AUTOSAR XML (schema 00047)
standard types defined: boolean, uint16, uint32, uint8
package /Application/AdaptiveApplicationSwComponentTypes
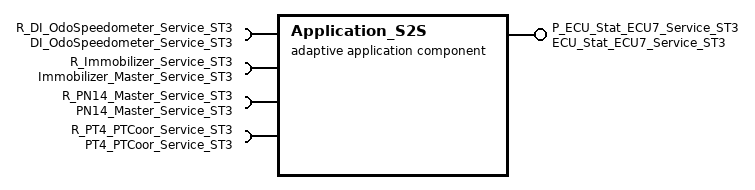
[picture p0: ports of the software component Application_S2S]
  adaptive application sw component type Application_S2S
    provide port P_ECU_Stat_ECU7_Service_ST3: provided-interface=ECU_Stat_ECU7_Service_ST3
    4 x require port:
      R_DI_OdoSpeedometer_Service_ST3: required-interface=DI_OdoSpeedometer_Service_ST3
      R_Immobilizer_Service_ST3: required-interface=Immobilizer_Master_Service_ST3
      R_PN14_Master_Service_ST3: required-interface=PN14_Master_Service_ST3
      R_PT4_PTCoor_Service_ST3: required-interface=PT4_PTCoor_Service_ST3
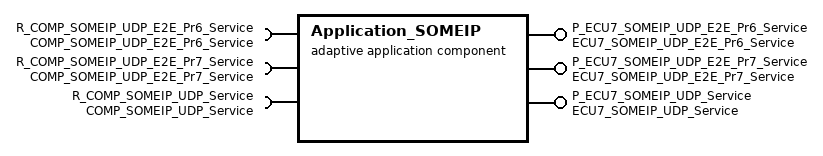
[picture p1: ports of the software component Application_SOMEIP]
  adaptive application sw component type Application_SOMEIP
    provide port P_ECU7_SOMEIP_UDP_E2E_Pr6_Service: provided-interface=ECU7_SOMEIP_UDP_E2E_Pr6_Service
    provide port P_ECU7_SOMEIP_UDP_E2E_Pr7_Service: provided-interface=ECU7_SOMEIP_UDP_E2E_Pr7_Service
    provide port P_ECU7_SOMEIP_UDP_Service: provided-interface=ECU7_SOMEIP_UDP_Service
    require port R_COMP_SOMEIP_UDP_E2E_Pr6_Service: required-interface=COMP_SOMEIP_UDP_E2E_Pr6_Service
    require port R_COMP_SOMEIP_UDP_E2E_Pr7_Service: required-interface=COMP_SOMEIP_UDP_E2E_Pr7_Service
    require port R_COMP_SOMEIP_UDP_Service: required-interface=COMP_SOMEIP_UDP_Service
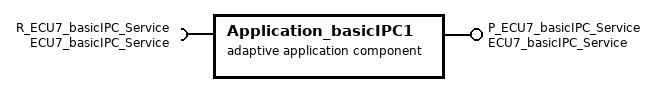
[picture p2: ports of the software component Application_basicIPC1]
  adaptive application sw component type Application_basicIPC1
    provide port P_ECU7_basicIPC_Service: provided-interface=ECU7_basicIPC_Service
    require port R_ECU7_basicIPC_Service: required-interface=ECU7_basicIPC_Service
  adaptive application sw component type Application_basicIPC2
    require port R_ECU7_basicIPC_Service: required-interface=ECU7_basicIPC_Service
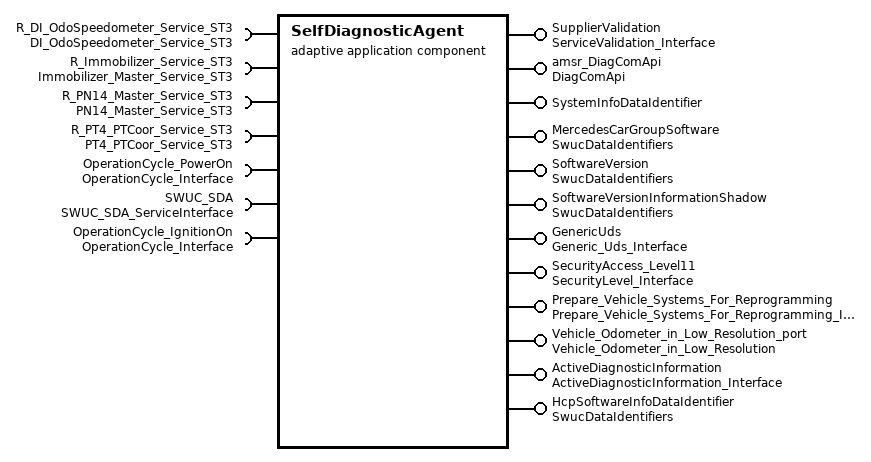
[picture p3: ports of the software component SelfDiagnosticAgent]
  adaptive application sw component type SelfDiagnosticAgent
    12 x provide port:
      SupplierValidation: provided-interface=ServiceValidation_Interface
      amsr_DiagComApi: provided-interface=DiagComApi
      SystemInfoDataIdentifier: provided-interface=SystemInfoDataIdentifier
      MercedesCarGroupSoftware: provided-interface=SwucDataIdentifiers
      SoftwareVersion: provided-interface=SwucDataIdentifiers
      SoftwareVersionInformationShadow: provided-interface=SwucDataIdentifiers
      GenericUds: provided-interface=Generic_Uds_Interface
      SecurityAccess_Level11: provided-interface=SecurityLevel_Interface
      Prepare_Vehicle_Systems_For_Reprogramming: provided-interface=Prepare_Vehicle_Systems_For_Reprogramming_Interface
      Vehicle_Odometer_in_Low_Resolution_port: provided-interface=Vehicle_Odometer_in_Low_Resolution
      ActiveDiagnosticInformation: provided-interface=ActiveDiagnosticInformation_Interface
      HcpSoftwareInfoDataIdentifier: provided-interface=SwucDataIdentifiers
    provide/require port prPortPrototype_FileStorage: provided-required-interface=PersistencyInterface_FileSotrage_PRPort
    provide/require port prPortPrototype_KeyValueStorage: provided-required-interface=PersistencyInterface_PRPort
    7 x require port:
      R_DI_OdoSpeedometer_Service_ST3: required-interface=DI_OdoSpeedometer_Service_ST3
      R_Immobilizer_Service_ST3: required-interface=Immobilizer_Master_Service_ST3
      R_PN14_Master_Service_ST3: required-interface=PN14_Master_Service_ST3
      R_PT4_PTCoor_Service_ST3: required-interface=PT4_PTCoor_Service_ST3
      OperationCycle_PowerOn: required-interface=OperationCycle_Interface
      SWUC_SDA: required-interface=SWUC_SDA_ServiceInterface
      OperationCycle_IgnitionOn: required-interface=OperationCycle_Interface
    adaptive swc internal behavior AdaptiveInternalBehavior
      13 x swc service dependency:
        OperationCyclePowerOn: assigned-ports=role-based-port-assignment={port-prototype=OperationCycle_PowerOn, role=SomeOtherRole}
        SwcDependency_SystemInfoDataIdentifier_Port: assigned-ports=role-based-port-assignment={port-prototype=SystemInfoDataIdentifier, role=DataServices}
        SwcDependency_MercedesCarGroupSoftware_Port: assigned-ports=role-based-port-assignment={port-prototype=MercedesCarGroupSoftware, role=DataServices}
        SwcDependency_SoftwareVersion_Port: assigned-ports=role-based-port-assignment={port-prototype=SoftwareVersion, role=DataServices}
        SwcDependency_SoftwareVersionInformationShadow_Port: assigned-ports=role-based-port-assignment={port-prototype=SoftwareVersionInformationShadow, role=DataServices}
        OperationCycleIgnitionOn: assigned-ports=role-based-port-assignment={port-prototype=OperationCycle_IgnitionOn, role=SomeOtherRole}
        SwcDependency_ServiceValidation_Supplier: assigned-ports=role-based-port-assignment={port-prototype=SupplierValidation, role=ServiceValidation}
          service-needs:
            diagnostic communication manager needs Supplier: service-request-callback-type=REQUEST-CALLBACK-TYPE-SUPPLIER
        GenericUds: assigned-ports=role-based-port-assignment={port-prototype=GenericUds, role=SomeOtherRole}
        SecurityAccess_Level11: assigned-ports=role-based-port-assignment={port-prototype=SecurityAccess_Level11, role=SomeOtherRole}
        Prepare_Vehicle_Systems_For_Reprogramming: assigned-ports=role-based-port-assignment={port-prototype=Prepare_Vehicle_Systems_For_Reprogramming, role=RoutineServices}
        SwcDependency_Vehicle_Odometer_in_Low_Resolution_Port: assigned-ports=role-based-port-assignment={port-prototype=Vehicle_Odometer_in_Low_Resolution_port, role=DataServices}
        SwcDependency_ActiveDiagnosticInformation_Port: assigned-ports=role-based-port-assignment={port-prototype=ActiveDiagnosticInformation, role=RoutineServices}
        SwcDependency_HcpSoftwareInfoDataIdentifier_Port: assigned-ports=role-based-port-assignment={port-prototype=HcpSoftwareInfoDataIdentifier, role=DataServices}
package /Application/Executables
  6 x executable, all with version=1.00.00.0000:
    Application_S2S_Executable: category=APPLICATION_LEVEL, build-type=BUILD-TYPE-DEBUG
      root sw component prototype Application_S2S_ExecutableRootSwc: application-type=Application_S2S
    Application_SOMEIP_Executable: category=APPLICATION_LEVEL, build-type=BUILD-TYPE-DEBUG
      root sw component prototype Application_SOMEIP_ExecutableRootSwc: application-type=Application_SOMEIP
    Application_basicIPC1_Executable: category=APPLICATION_LEVEL, build-type=BUILD-TYPE-DEBUG
      root sw component prototype Application_basicIPC1_ExecutableRootSwc: application-type=Application_basicIPC1
    Application_basicIPC2_Executable: category=APPLICATION_LEVEL, build-type=BUILD-TYPE-DEBUG
      root sw component prototype Application_basicIPC2_ExecutableRootSwc: application-type=Application_basicIPC2
    SelfDiagnosticAgent_Executable: category=APPLICATION_LEVEL, build-type=BUILD-TYPE-DEBUG
      root sw component prototype SelfDiagnosticAgent_ExecutableRootSwc: application-type=SelfDiagnosticAgent
    DiagnosticManagerDeamonExecutable: category=PLATFORM_LEVEL
      root sw component prototype DiagnosticManagerDeamonExecutableRootSwc: application-type=DiagnosticManagerSwc
package /ApplicationDeployment/Processes
  6 x process:
    Application_S2S_Process: executable=Application_S2S_Executable, state-dependent-startup-config{function-group-state=MachineState.Running, startup-config=STARTUP_CONFIG_DEFAULT}
    Application_SOMEIP_Process: executable=Application_SOMEIP_Executable, state-dependent-startup-config{function-group-state=MachineState.Running, startup-config=STARTUP_CONFIG_DEFAULT}
      process state machine ProcessStateMachine_Application_SOMEIP: type=MachineStates
    Application_basicIPC1_Process: executable=Application_basicIPC1_Executable, state-dependent-startup-config{function-group-state=MachineState.Running, startup-config=STARTUP_CONFIG_DEFAULT}
      process state machine ProcessStateMachine_Application_basicIPC1: type=MachineStates
    Application_basicIPC2_Process: executable=Application_basicIPC2_Executable, state-dependent-startup-config{function-group-state=MachineState.Running, startup-config=STARTUP_CONFIG_DEFAULT}
      process state machine ProcessStateMachine_Application_basicIPC2: type=MachineStates
    SelfDiagnosticAgent_Process: executable=SelfDiagnosticAgent_Executable, state-dependent-startup-config{function-group-state=MachineState.Running, startup-config=STARTUP_CONFIG_DEFAULT}
    DiagnosticManagerDeamon: design=DiagnosticManagerDeamonDesign, executable=DiagnosticManagerDeamonExecutable, state-dependent-startup-config{function-group-state=[MachineState.Startup, MachineState.Running], startup-config=STARTUP_CONFIG_DEFAULT}
package /ApplicationDeployment/ProcessDesigns
  6 x process design:
    Application_basicIPC1_ProcessDesign: executable=Application_basicIPC1_Executable
    Application_basicIPC2_ProcessDesign: executable=Application_basicIPC2_Executable
    DiagnosticManagerDeamonDesign: executable=DiagnosticManagerDeamonExecutable
    Application_SOMEIP_ProcessDesign: executable=Application_SOMEIP_Executable
    Application_S2S_ProcessDesign: executable=Application_S2S_Executable
    SelfDiagnosticAgent_ProcessDesign: executable=SelfDiagnosticAgent_Executable
package /Communication/PDUs
  general purpose pdu SD_Ctrl_Rx: category=SD, length=1472
  general purpose pdu SD_Ctrl_Rx_Multicast: category=SD, length=1472
  general purpose pdu SD_Ctrl_Tx: category=SD, length=1472
  pdu DI_OdoSpeedometer_ST3: length=8, unused-bit-pattern=255  # DriverInformation Odometer and speedometer
    signal CRC_DI_Odo_Pr5_ST3: start 0, 16 bit, little-endian, data-type-policy=OVERRIDE, i-signal-type=PRIMITIVE, base-type=uint16, range raw 0..65535 "16_CRC_w/oSNA_ImportedAdaptivePilot", to ECU7_ExecutionContext1  # CRC-checksum of signal group according to AUTOSAR Profile 5
    signal SQC_DI_Odo_Pr5_ST3: start 16, 8 bit, little-endian, data-type-policy=OVERRIDE, i-signal-type=PRIMITIVE, base-type=uint8, compu {identical}, range raw 0..255 "08_0-255_1_SNA=-", to ECU7_ExecutionContext1  # Sequence counter
    signal Odo_ST3: start 24, 24 bit, little-endian, data-type-policy=OVERRIDE, i-signal-type=PRIMITIVE, base-type=uint32, invalid-value=16777215, compu {phys=raw*0.1 for raw 0..9999999, 16777214=I_C24_KM_0_999999K9_0K1_INVLD_SNA_INVLD (INVLD) (Invalid), 16777215=I_C24_KM_0_999999K9_0K1_INVLD_SNA_SNA (SNA) (SNA value from data type); unit km}, range phys 0..1677721.5 "24_km_0-999999,9_0,1_Invld_SNA", to ECU7_ExecutionContext1  # Odometer (for everyone)
    mapping DI_Odo_Pr5_ST3: i-signal-group=DI_Odo_Pr5_ST3, transfer-property=PENDING
    mapping VehSpd_Disp_ST3: transfer-property=PENDING
  pdu ECU_Stat_ECU7_ST3: length=8, unused-bit-pattern=0  # ECU state
    signal ECU_Id_ECU7_ST3: start 0, 12 bit, little-endian, data-type-policy=OVERRIDE, i-signal-type=PRIMITIVE, base-type=uint16, invalid-value=4095, compu {phys=raw for raw 0..4094, 4095=I_C12_0_4094_1_SNA_SNA (SNA) (SNA value from data type)}, range phys 0..4095 "12_0-4094_1_SNA", transfer-property=PENDING  # ECU identifier
    signal WakeupRsn_ECU7_ST3: start 20, 10 bit, little-endian, data-type-policy=OVERRIDE, i-signal-type=PRIMITIVE, base-type=uint16, invalid-value=1023, compu {0=I_C10_WAKEUPRSN_ST3_NETWORK (NETWORK) (Wakeup by network), 1=I_C10_WAKEUPRSN_ST3_NW_MAIN (NW_MAIN) (Wakeup by MAIN Ethernet), 11=I_C10_WAKEUPRSN_ST3_NW_HEADUNIT1 (NW_HEADUNIT1) (Wakeup by HEADUNIT1 CAN), 12=I_C10_WAKEUPRSN_ST3_NW_HEADUNIT2 (NW_HEADUNIT2) (Wakeup by HEADUNIT2 CAN), 13=I_C10_WAKEUPRSN_ST3_NW_PERIPHERY (NW_PERIPHERY) (Wakeup by PERIPHERY CAN), 14=I_C10_WAKEUPRSN_ST3_NW_BODY1 (NW_BODY1) (Wakeup by BODY1 CAN), 15=I_C10_WAKEUPRSN_ST3_NW_CHASSIS (NW_CHASSIS) (Wakeup by CHASSIS FlexRay), 16=I_C10_WAKEUPRSN_ST3_NW_RADAR_R (NW_RADAR_R) (Wakeup by RADAR_R CAN), 17=I_C10_WAKEUPRSN_ST3_NW_RADAR_F (NW_RADAR_F) (Wakeup by RADAR_F CAN), 18=I_C10_WAKEUPRSN_ST3_NW_OBD_PTI (NW_OBD_PTI) (Wakeup by OBD_PTI CAN), 19=I_C10_WAKEUPRSN_ST3_NW_STEERING_WHEEL (NW_STEERING_WHEEL) (Wakeup by STEERING_WHEEL CAN), 20=I_C10_WAKEUPRSN_ST3_NW_CPC (NW_CPC) (Wakeup by CPC CAN), 21=I_C10_WAKEUPRSN_ST3_NW_ECM (NW_ECM) (Wakeup by ECM CAN), 22=I_C10_WAKEUPRSN_ST3_NW_ENERGY (NW_ENERGY) (Wakeup by ENERGY CAN), 23=I_C10_WAKEUPRSN_ST3_NW_INV (NW_INV) (Wakeup by INV CAN), 24=I_C10_WAKEUPRSN_ST3_NW_TCM (NW_TCM) (Wakeup by TCM CAN), 25=I_C10_WAKEUPRSN_ST3_NW_AEPU (NW_AEPU) (Wakeup by AEPU CAN), 26=I_C10_WAKEUPRSN_ST3_NW_BODY2 (NW_BODY2) (Wakeup by BODY2 CAN), 27=I_C10_WAKEUPRSN_ST3_NW_BODY3 (NW_BODY3) (Wakeup by BODY3 CAN), 28=I_C10_WAKEUPRSN_ST3_NW_CAL_COC (NW_CAL_COC) (Wakeup by CAL_COC CAN), 29=I_C10_WAKEUPRSN_ST3_NW_CAL_DL (NW_CAL_DL) (Wakeup by CAL_DL CAN), 30=I_C10_WAKEUPRSN_ST3_NW_CAL_DR (NW_CAL_DR) (Wakeup by CAL_DR CAN), 31=I_C10_WAKEUPRSN_ST3_NW_ECM_PERIPHERY1 (NW_ECM_PERIPHERY1) (Wakeup by ECM_PERIPHERY1 CAN), 32=I_C10_WAKEUPRSN_ST3_NW_ECM_PERIPHERY2 (NW_ECM_PERIPHERY2) (Wakeup by ECM_PERIPHERY2 CAN), 33=I_C10_WAKEUPRSN_ST3_NW_ENGINE_PT3 (NW_ENGINE_PT3) (Wakeup by ENGINE_PT3 CAN), 34=I_C10_WAKEUPRSN_ST3_NW_HAD_BACKUP (NW_HAD_BACKUP) (Wakeup by HAD_BACKUP CAN), 35=I_C10_WAKEUPRSN_ST3_NW_HYBRID_PT3 (NW_HYBRID_PT3) (Wakeup by HYBRID_PT3 CAN), 36=I_C10_WAKEUPRSN_ST3_NW_LSM_F (NW_LSM_F) (Wakeup by LSM_F CAN), 37=I_C10_WAKEUPRSN_ST3_NW_POWERTRAIN_PT3 (NW_POWERTRAIN_PT3) (Wakeup by POWERTRAIN_PT3 CAN), 38=I_C10_WAKEUPRSN_ST3_NW_PT_SENSOR_PT3 (NW_PT_SENSOR_PT3) (Wakeup by PT_SENSOR_PT3 CAN), 39=I_C10_WAKEUPRSN_ST3_NW_RVC_HSVL (NW_RVC_HSVL) (Wakeup by RVC_HSVL CAN), 40=I_C10_WAKEUPRSN_ST3_NW_SPV (NW_SPV) (Wakeup by SPV CAN), 41=I_C10_WAKEUPRSN_ST3_NW_SUSPENSION_F (NW_SUSPENSION_F) (Wakeup by SUSPENSION_F CAN), 42=I_C10_WAKEUPRSN_ST3_NW_SUSPENSION_R (NW_SUSPENSION_R) (Wakeup by SUSPENSION_R CAN), 43=I_C10_WAKEUPRSN_ST3_NW_EIS_BASE_GW (NW_EIS_BASE_GW) (Wakeup by EIS_BASE_GW CAN), 44=I_C10_WAKEUPRSN_ST3_NW_EIS_GW_BASE (NW_EIS_GW_BASE) (Wakeup by EIS_GW_BASE CAN), 45=I_C10_WAKEUPRSN_ST3_NW_AUXILIARY1 (NW_AUXILIARY1) (Wakeup by AUXILIARY1 CAN), 46=I_C10_WAKEUPRSN_ST3_NW_AUXILIARY2 (NW_AUXILIARY2) (Wakeup by AUXILIARY2 CAN), 47=I_C10_WAKEUPRSN_ST3_NW_DRIVE_UNIT (NW_DRIVE_UNIT) (Wakeup by DRIVE_UNIT CAN), 48=I_C10_WAKEUPRSN_ST3_NW_INLET (NW_INLET) (Wakeup by INLET CAN), 49=I_C10_WAKEUPRSN_ST3_NW_BODY4 (NW_BODY4) (Wakeup by BODY4 CAN), 115=I_C10_WAKEUPRSN_ST3_LIN_HVAC_F (LIN_HVAC_F) (Wakeup by LIN-Slave HVAC_F), 116=I_C10_WAKEUPRSN_ST3_LIN_HVAC_R (LIN_HVAC_R) (Wakeup by LIN-Slave HVAC_R), 117=I_C10_WAKEUPRSN_ST3_LIN_VCS (LIN_VCS) (Wakeup by LIN-Slave VCS), 118=I_C10_WAKEUPRSN_ST3_LIN_WPRA (LIN_WPRA) (Wakeup by LIN-Slave WPRA), 119=I_C10_WAKEUPRSN_ST3_LIN_IHTM_RC (LIN_IHTM_RC) (Wakeup by LIN-Slave IHTM_RC), 120=I_C10_WAKEUPRSN_ST3_LIN_PTC48_R (LIN_PTC48_R) (Wakeup by LIN-Slave PTC48_R), 121=I_C10_WAKEUPRSN_ST3_LIN_AQS (LIN_AQS) (Wakeup by LIN-Slave AQS), 122=I_C10_WAKEUPRSN_ST3_LIN_ECP2_1 (LIN_ECP2_1) (Wakeup by LIN-Slave ECP2_1), 123=I_C10_WAKEUPRSN_ST3_LIN_EXV1 (LIN_EXV1) (Wakeup by LIN-Slave EXV1), 124=I_C10_WAKEUPRSN_ST3_LIN_IHTM (LIN_IHTM) (Wakeup by LIN-Slave IHTM), 125=I_C10_WAKEUPRSN_ST3_LIN_EAC (LIN_EAC) (Wakeup by LIN-Slave EAC), 126=I_C10_WAKEUPRSN_ST3_LIN_EAC48 (LIN_EAC48) (Wakeup by LIN-Slave EAC48), 127=I_C10_WAKEUPRSN_ST3_LIN_PTC_HV (LIN_PTC_HV) (Wakeup by LIN-Slave PTC_HV), 128=I_C10_WAKEUPRSN_ST3_TERM_15 (TERM_15) (Wakeup by discrete terminal 15 signal), 130=I_C10_WAKEUPRSN_ST3_TERM_54 (TERM_54) (Wakeup by terminal 54 active), 131=I_C10_WAKEUPRSN_ST3_LIN_HFA (LIN_HFA) (Wakeup by LIN-Slave Hands Free Access), 132=I_C10_WAKEUPRSN_ST3_LIN_IBS (LIN_IBS) (Wakeup by LIN-Slave Battery sensor), 133=I_C10_WAKEUPRSN_ST3_LIN_DOOR_HANDLE (LIN_DOOR_HANDLE) (Wakeup by LIN-Slave Door Handle), 134=I_C10_WAKEUPRSN_ST3_LIN_LISB48 (LIN_LISB48) (Wakeup by LIN-Slave LISB48), 135=I_C10_WAKEUPRSN_ST3_CMN_ECU_RST_POR (CMN_ECU_RST_POR) (Wakeup by ECU Power On Reset, Common Reason), 136=I_C10_WAKEUPRSN_ST3_CMN_ECU_RST_DIAG (CMN_ECU_RST_DIAG) (Wakeup by ECU Diagnostic Reset, Common Reason), 137=I_C10_WAKEUPRSN_ST3_CMN_ECU_RST_TEST (CMN_ECU_RST_TEST) (Wakeup by ECU Test Reset, Common Reason), 138=I_C10_WAKEUPRSN_ST3_CMN_ECU_RST_ERR (CMN_ECU_RST_ERR) (Wakeup by ECU Error Reset, Common Reason), 139=I_C10_WAKEUPRSN_ST3_CMN_ETH_WAKEUPLINE (CMN_ETH_WAKEUPLINE) (Wakeup by Ethernet Wakeup-Line, Common Reason), 140=I_C10_WAKEUPRSN_ST3_CMN_AFTERRUN (CMN_AFTERRUN) (Wakeup by afterrun, Common Reason), 141=I_C10_WAKEUPRSN_ST3_CRASH (CRASH) (Wakeup by crash signal), 142=I_C10_WAKEUPRSN_ST3_LIN_VCI (LIN_VCI) (Wakeup by LIN-Slave VCI), 143=I_C10_WAKEUPRSN_ST3_LIN_CIS (LIN_CIS) (Wakeup by LIN-Slave CIS), 181=I_C10_WAKEUPRSN_ST3_EASY_ENTRY_ACTV (EASY_ENTRY_ACTV) (Wakeup by Easy Entry active), 183=I_C10_WAKEUPRSN_ST3_ERR_SEAT_HTVN (ERR_SEAT_HTVN) (Wakeup by error seat heating/ventilation), 184=I_C10_WAKEUPRSN_ST3_ERR_SEAT_CHM (ERR_SEAT_CHM) (Wakeup by error console heating), 199=I_C10_WAKEUPRSN_ST3_VEHSL_EVENT (VEHSL_EVENT) (Wakeup by Vehicle State Living signal update), 200=I_C10_WAKEUPRSN_ST3_RLS (RLS) (Wakeup by rotary light switch), 201=I_C10_WAKEUPRSN_ST3_EF_KEY (EF_KEY) (Wakeup by emergency flasher key), 202=I_C10_WAKEUPRSN_ST3_RHU_FT (RHU_FT) (Wakeup by residual heat utilization front), 203=I_C10_WAKEUPRSN_ST3_RHU_R (RHU_R) (Wakeup by residual heat utilization rear), 204=I_C10_WAKEUPRSN_ST3_ICH_RQ (ICH_RQ) (Wakeup by idependent car heater request), 205=I_C10_WAKEUPRSN_ST3_VPRZR_VN (VPRZR_VN) (Wakeup by Vaporizer ventilation), 206=I_C10_WAKEUPRSN_ST3_PRECON (PRECON) (Wakeup by PreConditioning), 207=I_C10_WAKEUPRSN_ST3_SOL_VN (SOL_VN) (Wakeup by Solar Ventilation), 208=I_C10_WAKEUPRSN_ST3_EXTLGT_ACTV (EXTLGT_ACTV) (Wakeup by exterior lighting active), 209=I_C10_WAKEUPRSN_ST3_INTLGT_ACTV (INTLGT_ACTV) (Wakeup by interior lighting active), 210=I_C10_WAKEUPRSN_ST3_TSSR_ACTV (TSSR_ACTV) (Wakeup by TSSR active), 211=I_C10_WAKEUPRSN_ST3_SEAT_HT_F_ACTV (SEAT_HT_F_ACTV) (Wakeup by seat heating front active), 212=I_C10_WAKEUPRSN_ST3_SEAT_HT_R_ACTV (SEAT_HT_R_ACTV) (Wakeup by seat heating rear active), 213=I_C10_WAKEUPRSN_ST3_SEAT_VN_F_ACTV (SEAT_VN_F_ACTV) (Wakeup by seat ventilation front active), 214=I_C10_WAKEUPRSN_ST3_SEAT_VN_R_ACTV (SEAT_VN_R_ACTV) (Wakeup by seat ventilation rear active), 215=I_C10_WAKEUPRSN_ST3_EHS_3S (EHS_3S) (Wakeup by 3S engine hood switch (Pawl)), 216=I_C10_WAKEUPRSN_ST3_T58D_POTI (T58D_POTI) (Wakeup by terminal 58d potentiometer), 217=I_C10_WAKEUPRSN_ST3_DRB (DRB) (Wakeup by Double Roller Blind), 218=I_C10_WAKEUPRSN_ST3_BKRST_UNLK_RM (BKRST_UNLK_RM) (Wakeup by Backrest Unlock rear Middle), 219=I_C10_WAKEUPRSN_ST3_DL_SW2_PSD (DL_SW2_PSD) (Wakeup by Deck Lid Switch Pressed 2), 220=I_C10_WAKEUPRSN_ST3_DL_SW (DL_SW) (Wakeup by deck lid switch pressed), 221=I_C10_WAKEUPRSN_ST3_BGC_SW (BGC_SW) (Wakeup by switch inside baggage compartment pressed), 222=I_C10_WAKEUPRSN_ST3_BKRST_RL_LK_UNLK (BKRST_RL_LK_UNLK) (Wakeup by back rest rear left locked or unlocked), 223=I_C10_WAKEUPRSN_ST3_BKRST_RR_LK_UNLK (BKRST_RR_LK_UNLK) (Wakeup by back rest rear right locked or unlocked), 224=I_C10_WAKEUPRSN_ST3_DL_CLS_LK_SW (DL_CLS_LK_SW) (Wakeup by deck lid switch close/lock close pressed), 225=I_C10_WAKEUPRSN_ST3_DL_RLTCH (DL_RLTCH) (Wakeup by deck lid rotary latch pressed), 226=I_C10_WAKEUPRSN_ST3_BKRST_3L_LK_UNLK (BKRST_3L_LK_UNLK) (Wakeup by back rest 3rd row left locked or unlocked), 227=I_C10_WAKEUPRSN_ST3_BKRST_3R_LK_UNLK (BKRST_3R_LK_UNLK) (Wakeup by back rest 3rd row right locked or unlocked), 228=I_C10_WAKEUPRSN_ST3_GAS_DR_SW (GAS_DR_SW) (Wakeup by gas door switch), 229=I_C10_WAKEUPRSN_ST3_AILCF (AILCF) (Wakeup by AILCF), 230=I_C10_WAKEUPRSN_ST3_AILCC (AILCC) (Wakeup by AILCC), 256=I_C10_WAKEUPRSN_ST3_TRLR_ELEC_ACT (TRLR_ELEC_ACT) (Wakeup by electrical trailer hitch activation), 257=I_C10_WAKEUPRSN_ST3_TRLR_DET (TRLR_DET) (Wakeup by trailer detected), 258=I_C10_WAKEUPRSN_ST3_DL_LK (DL_LK) (Wakeup by delayed locking), 259=I_C10_WAKEUPRSN_ST3_START_SW_PSD (START_SW_PSD) (Wakeup by start switch pressed), 260=I_C10_WAKEUPRSN_ST3_RADIO_DATA (RADIO_DATA) (Wakeup by radio data), 261=I_C10_WAKEUPRSN_ST3_RLTCH_DR (RLTCH_DR) (Wakeup by rotational latch door), 263=I_C10_WAKEUPRSN_ST3_PKBRKSW (PKBRKSW) (Wakeup by Parking switch pressed), 264=I_C10_WAKEUPRSN_ST3_KEYLESS_GO (KEYLESS_GO) (Wakeup by Keyless Go/Start (Core 1/0)), 265=I_C10_WAKEUPRSN_ST3_PNM12 (PNM12) (Wakeup by Power network management 12V), 266=I_C10_WAKEUPRSN_ST3_PNM48 (PNM48) (Wakeup by Power network management 48V), 267=I_C10_WAKEUPRSN_ST3_BAT48_LOWCHARGE (BAT48_LOWCHARGE) (Wakeup by 48V battery due to low charge), 270=I_C10_WAKEUPRSN_ST3_PN14_IODM (PN14_IODM) (Wakeup by IOD Measurement), 271=I_C10_WAKEUPRSN_ST3_PN14_REMSRV_STAT (PN14_REMSRV_STAT) (Wakeup by Change of Remote Service Status), 272=I_C10_WAKEUPRSN_ST3_PN14_DDP (PN14_DDP) (Wakeup by Deep Discharge Protection), 273=I_C10_WAKEUPRSN_ST3_PN14_LOWCHARGE (PN14_LOWCHARGE) (Wakeup by low charge of the battery), 274=I_C10_WAKEUPRSN_ST3_PN14_REMODHV12V (PN14_REMODHV12V) (Wakeup by reload mode HV 12V), 275=I_C10_WAKEUPRSN_ST3_PN14_DLM (PN14_DLM) (Wakeup by Powernet CutOff (Dynamic Load Management)), 276=I_C10_WAKEUPRSN_ST3_SDC_PN2_LOWCHARGE (SDC_PN2_LOWCHARGE) (Wakeup by low charge of the battery in SDC_PNM2), 277=I_C10_WAKEUPRSN_ST3_SDC_PN2_REMODHV12V (SDC_PN2_REMODHV12V) (Wakeup by reload mode HV 12 in SDC_PNM2), 280=I_C10_WAKEUPRSN_ST3_DATA_EXCHG (DATA_EXCHG) (Wakeup by data exchange with vehicle functions), 281=I_C10_WAKEUPRSN_ST3_INTERNET_CON (INTERNET_CON) (Wakeup by internet connection), 282=I_C10_WAKEUPRSN_ST3_CMN_USER_DATA (CMN_USER_DATA) (Wakeup by user data, Common Reason), 290=I_C10_WAKEUPRSN_ST3_CMN_SERV_LOCAL (CMN_SERV_LOCAL) (Wakeup by local activated service, Common Reason), 291=I_C10_WAKEUPRSN_ST3_CMN_SERV_REM (CMN_SERV_REM) (Wakeup by remote activated service, Common Reason), 292=I_C10_WAKEUPRSN_ST3_VEH_REAR_LOWERING (VEH_REAR_LOWERING) (Wakeup by vehicle rear lowering), 300=I_C10_WAKEUPRSN_ST3_CMN_BTN_PSD (CMN_BTN_PSD) (Wakeup by button pressed, Common Reason), 301=I_C10_WAKEUPRSN_ST3_FLAP_PSD (FLAP_PSD) (Wakeup by flap pressed), 302=I_C10_WAKEUPRSN_ST3_CHADEMO (CHADEMO) (Wakeup by CHADEMO charging system), 303=I_C10_WAKEUPRSN_ST3_GBT (GBT) (Wakeup by GBT charging system), 304=I_C10_WAKEUPRSN_ST3_CMN_PROXIMITY (CMN_PROXIMITY) (Wakeup by proximity, Common Reason), 305=I_C10_WAKEUPRSN_ST3_CTRL_PILOT (CTRL_PILOT) (Wakeup by control pilot), 306=I_C10_WAKEUPRSN_ST3_CMN_HV_DET (CMN_HV_DET) (Wakeup by HiVolt detection, Common Reason), 307=I_C10_WAKEUPRSN_ST3_CMN_CHRG_TMR (CMN_CHRG_TMR) (Wakeup by charging timer, Common Reason), 308=I_C10_WAKEUPRSN_ST3_TRCT_BAT_OP_STRATEGY (TRCT_BAT_OP_STRATEGY) (Wakeup by traction battery operating strategy), 309=I_C10_WAKEUPRSN_ST3_VTA (VTA) (Wakeup by VTA alarm), 310=I_C10_WAKEUPRSN_ST3_PDD (PDD) (Wakeup by PDD collision detected), 311=I_C10_WAKEUPRSN_ST3_UNEQUAL_STRING_VOLT (UNEQUAL_STRING_VOLT) (Wakeup by unequal string voltages), 312=I_C10_WAKEUPRSN_ST3_MUTE_ACTV (MUTE_ACTV) (Wakeup by mute activated), 313=I_C10_WAKEUPRSN_ST3_VIDEO_RQ (VIDEO_RQ) (Wakeup by video in request), 314=I_C10_WAKEUPRSN_ST3_ALARM_ACTV (ALARM_ACTV) (Wakeup by alarm activation), 315=I_C10_WAKEUPRSN_ST3_RECIRC_AIR_RQ (RECIRC_AIR_RQ) (Wakeup by FLA/NFS recirc air request), 316=I_C10_WAKEUPRSN_ST3_TPM_SYNC (TPM_SYNC) (Wakeup by TPM synchronize BackEndServer), 320=I_C10_WAKEUPRSN_ST3_DI_DISP_RQ (DI_DISP_RQ) (Wakeup by DI display request), 321=I_C10_WAKEUPRSN_ST3_DI_IND_RQ (DI_IND_RQ) (Wakeup by DI indicator request), 322=I_C10_WAKEUPRSN_ST3_HUD_RQ (HUD_RQ) (Wakeup by HUD request), 325=I_C10_WAKEUPRSN_ST3_MSG_DISP_RQ (MSG_DISP_RQ) (Wakeup by message display request), 326=I_C10_WAKEUPRSN_ST3_ROOF_LMP_ON_RQ (ROOF_LMP_ON_RQ) (Wakeup by rooflamps on request), 327=I_C10_WAKEUPRSN_ST3_IL_ON_RQ (IL_ON_RQ) (Wakeup by interior light activated from special vehicle), 328=I_C10_WAKEUPRSN_ST3_SPS_APPL (SPS_APPL) (Wakeup by special vehicle application), 330=I_C10_WAKEUPRSN_ST3_PWC_WRAPPER (PWC_WRAPPER) (Wakeup by PWC Wrapper), 331=I_C10_WAKEUPRSN_ST3_PW_SW (PW_SW) (Wakeup by power window switch), 332=I_C10_WAKEUPRSN_ST3_CLKS_SW (CLKS_SW) (Wakeup by centrol locking system switch), 333=I_C10_WAKEUPRSN_ST3_SEAT_SW (SEAT_SW) (Wakeup by seat switch), 334=I_C10_WAKEUPRSN_ST3_DL_REM_SW (DL_REM_SW) (Wakeup by deck lid remote switch), 335=I_C10_WAKEUPRSN_ST3_TANK_UNLK_SW (TANK_UNLK_SW) (Wakeup by tank unlock switch), 336=I_C10_WAKEUPRSN_ST3_SLTCH_DR (SLTCH_DR) (Wakeup by secondary latch), 337=I_C10_WAKEUPRSN_ST3_INSRLVR_SW (INSRLVR_SW) (Wakeup by inside release lever switch), 338=I_C10_WAKEUPRSN_ST3_OUTSRLVR_SW (OUTSRLVR_SW) (Wakeup by outside release lever switch), 339=I_C10_WAKEUPRSN_ST3_TRL_HTCH_SW (TRL_HTCH_SW) (Wakeup by trailer hitch switch), 340=I_C10_WAKEUPRSN_ST3_TSSR_R_RB_SW (TSSR_R_RB_SW) (Wakeup by TSSR switch), 341=I_C10_WAKEUPRSN_ST3_CSL_SW (CSL_SW) (Wakeup by child security switch), 342=I_C10_WAKEUPRSN_ST3_GEAR_SW (GEAR_SW) (Wakeup by gear switch), 343=I_C10_WAKEUPRSN_ST3_AD_SW (AD_SW) (Wakeup by automated door switch), 344=I_C10_WAKEUPRSN_ST3_T2R_SW (T2R_SW) (Wakeup by automated door Tip2Run), 345=I_C10_WAKEUPRSN_ST3_HV_INTERLOCK_ERR (HV_INTERLOCK_ERR) (Wakeup by interlock error), 346=I_C10_WAKEUPRSN_ST3_NFC (NFC) (Wakeup by NFC), 347=I_C10_WAKEUPRSN_ST3_POLLING (POLLING) (Wakeup by Polling (COD belonging to the car was detected)), 348=I_C10_WAKEUPRSN_ST3_TSL_P_PSD (TSL_P_PSD) (Wakeup by Transmission Selector Lever P button pressed), 349=I_C10_WAKEUPRSN_ST3_STWHL_LVR_PSD (STWHL_LVR_PSD) (Wakeup by Steering Wheel Lever pressed), 350=I_C10_WAKEUPRSN_ST3_BAT14_DDP (BAT14_DDP) (Wakeup by Deep discharge protection), 351=I_C10_WAKEUPRSN_ST3_BAT14_LOWCHARGE (BAT14_LOWCHARGE) (Wakeup by low charge of the 12V battery), 352=I_C10_WAKEUPRSN_ST3_BAT14_CHARGECURR (BAT14_CHARGECURR) (Wakeup by charge Current detection), 353=I_C10_WAKEUPRSN_ST3_BAT14_IODM (BAT14_IODM) (Wakeup by IOD Measurement), 354=I_C10_WAKEUPRSN_ST3_BAT14_IODAVG (BAT14_IODAVG) (Wakeup by Average IOD Measurement), 400=I_C10_WAKEUPRSN_ST3_FOTA_TMR (FOTA_TMR) (Wakeup by FOTA Timer), 1020=I_C10_WAKEUPRSN_ST3_RESERVE_3 (RESERVE_3) (Wakeup by Reserve 3), 1021=I_C10_WAKEUPRSN_ST3_RESERVE_2 (RESERVE_2) (Wakeup by Reserve 2), 1022=I_C10_WAKEUPRSN_ST3_RESERVE_1 (RESERVE_1) (Wakeup by Reserve 1), 1023=I_C10_WAKEUPRSN_ST3_SNA (SNA) (SNA value from data type)} "1 - 99: Networks,e.g. MAIN Wakeup by MAIN - CHASSIS Wakeup by CHASSIS -ENGINE Wakeup by ENGINE | What about LIN? 100 - 1022: ECU-specific wakeup reasons, generically so that the reasons can be used by all ECUs", range raw 0..1023 "10_WakeupRsn_ST3", transfer-property=PENDING  # Wakeup reason
    signal Awake_Diag_Actv_ECU7_ST3: start 30, 1 bit, little-endian, data-type-policy=OVERRIDE, i-signal-type=PRIMITIVE, base-type=boolean, transfer-property=PENDING  # Stay awake for diagnostics active
    signal Awake_NwStart_ECU7_ST3: start 31, 1 bit, little-endian, data-type-policy=OVERRIDE, i-signal-type=PRIMITIVE, base-type=boolean, transfer-property=PENDING  # Stay awake for network startup
    signal Awake_HAD_Actv_ECU7_ST3: start 32, 1 bit, little-endian, data-type-policy=OVERRIDE, i-signal-type=PRIMITIVE, base-type=boolean, transfer-property=PENDING  # Stay awake for HAD active
    signal Awake_Ignition_On_ECU7_ST3: start 33, 1 bit, little-endian, data-type-policy=OVERRIDE, i-signal-type=PRIMITIVE, base-type=boolean, transfer-property=PENDING  # Stay awake for ignition on from ECU7
  pdu Ign_Stat_ST3: length=4, minimum-delay=0.02, unused-bit-pattern=255  # Ignition state
    signal CRC_Ign_Stat_Pr5_ST3: start 0, 16 bit, little-endian, data-type-policy=OVERRIDE, i-signal-type=PRIMITIVE, base-type=uint16, range raw 0..65535 "16_CRC_w/oSNA_ImportedAdaptivePilot", transfer-property=PENDING, to ECU7_ExecutionContext1  # CRC-checksum of signal group according to AUTOSAR Profile 5
    signal SQC_Ign_Stat_Pr5_ST3: start 16, 8 bit, little-endian, data-type-policy=OVERRIDE, i-signal-type=PRIMITIVE, base-type=uint8, compu {identical}, range phys 0..255 "08_0-255_1_SNA=-", transfer-property=PENDING, to ECU7_ExecutionContext1  # Sequence counter
    signal ISw_Stat_ST3: start 24, 3 bit, little-endian, data-type-policy=OVERRIDE, i-signal-type=PRIMITIVE, base-type=uint8, invalid-value=7, compu {0=I_C03_ISW_STAT_IGN_LOCK (IGN_LOCK) (Ignition lock (0)), 1=I_C03_ISW_STAT_IGN_OFF (IGN_OFF) (Ignition off (15c)), 2=I_C03_ISW_STAT_IGN_ACC (IGN_ACC) (Ignition accessory (15r)), 4=I_C03_ISW_STAT_IGN_ON (IGN_ON) (Ignition on (15)), 5=I_C03_ISW_STAT_IGN_START (IGN_START) (Ignition start (50)), 7=I_C03_ISW_STAT_SNA (SNA) (SNA value from data type)}, range raw 0..7 "03_ISw_Stat", to ECU7_ExecutionContext1  # Ignition switch state
    signal Veh_Op_Mode_ST3: start 27, 4 bit, little-endian, data-type-policy=OVERRIDE, i-signal-type=PRIMITIVE, base-type=uint8, invalid-value=15, compu {0=I_C04_VEHOPMODE_DRV (DRV) (Drive), 1=I_C04_VEHOPMODE_DIAG (DIAG) (Diagnostic), 2=I_C04_VEHOPMODE_REMSTART_PRECON (REMSTART_PRECON) (Remote_start preconditioning), 3=I_C04_VEHOPMODE_ENG_RUN_CONT (ENG_RUN_CONT) (Engine continuos running), 4=I_C04_VEHOPMODE_KEY_PARK (KEY_PARK) (Key_parking), 5=I_C04_VEHOPMODE_REMSTART_BAT_CHRG (REMSTART_BAT_CHRG) (Remote start battery charge), 6=I_C04_VEHOPMODE_AVP (AVP) (Automated Valet Parking), 7=I_C04_VEHOPMODE_SDC (SDC) (Self Driving Car), 15=I_C04_VEHOPMODE_SNA (SNA) (SNA value from data type)}, range raw 0..15 "04_VehOpMode", transfer-property=PENDING, to ECU7_ExecutionContext1  # Operating Mode Vehicle
    signal KG_StartSw_Psd_ST3: start 31, 1 bit, little-endian, data-type-policy=OVERRIDE, i-signal-type=PRIMITIVE, base-type=boolean, transfer-property=PENDING, to ECU7_ExecutionContext1  # Keyless Go start switch pressed
    mapping Ign_Stat_Pr5_ST3: i-signal-group=Ign_Stat_Pr5_ST3, transfer-property=TRIGGERED-ON-CHANGE
  pdu PN14_Master_Stat1_ST3: length=8, unused-bit-pattern=255  # Powernetwork 12V master state
    signal PN14_TransMd_Stat_ST3: start 0, 2 bit, little-endian, data-type-policy=OVERRIDE, i-signal-type=PRIMITIVE, base-type=uint8, invalid-value=3, compu {0=I_C02_TRANSMD_STAT_OFF (OFF) (Transport mode permanently off), 1=I_C02_TRANSMD_STAT_TEMP_OFF (TEMP_OFF) (Transport mode temporarily off), 2=I_C02_TRANSMD_STAT_ACTV (ACTV) (Transport mode active), 3=I_C02_TRANSMD_STAT_SNA (SNA) (SNA value from data type)}, range raw 0..3 "02_TransMd_Stat", transfer-property=PENDING, to ECU7_ExecutionContext1  # Powernet transport mode status
    signal PN14_ProdMd_Stat_ST3: start 5, 3 bit, little-endian, data-type-policy=OVERRIDE, i-signal-type=PRIMITIVE, base-type=uint8, invalid-value=7, compu {0=I_C03_PN14_PRODMD_STAT_ST3_OFF (OFF) (Productionmode off), 1=I_C03_PN14_PRODMD_STAT_ST3_ON (ON) (Productionmode active), 2=I_C03_PN14_PRODMD_STAT_ST3_SF01 (SF01) (Productionmode Special Funcion 1), 3=I_C03_PN14_PRODMD_STAT_ST3_SF02 (SF02) (Productionmode Special Funcion 2), 4=I_C03_PN14_PRODMD_STAT_ST3_SF03 (SF03) (Productionmode Special Funcion 3), 7=I_C03_PN14_PRODMD_STAT_ST3_SNA (SNA) (SNA value from data type)}, range raw 0..7 "03_PN14_ProdMd_Stat_ST3", transfer-property=PENDING, to ECU7_ExecutionContext1  # Powernet production mode state
    signal PN14_SupBat_Volt_ST3: start 22, 10 bit, little-endian, data-type-policy=OVERRIDE, i-signal-type=PRIMITIVE, base-type=uint16, invalid-value=1023, compu {phys=raw*0.025 for raw 0..1022, 1023=I_C10_V_0_25K55_0K025_SNA (SNA) (SNA value from data type); unit V}, range phys 0..25.575 "10_V_0-25,55_0,025", transfer-property=PENDING, to ECU7_ExecutionContext1  # Supply battery voltage
    mapping PN14_DDP_Sw_Stat_ST3: transfer-property=PENDING
    mapping PN14_ExtBat_Charge_Actv_ST3: transfer-property=PENDING
    mapping PN14_PNSec_RechargeEnable_ST3: transfer-property=PENDING
    mapping PN14_ProdMd_BatStat_ST3: transfer-property=PENDING
    mapping PN14_SupBat_Curr_ST3: transfer-property=PENDING
    mapping PN14_SupBat_Stat_ST3: transfer-property=PENDING
    mapping PN14_SupBat_Temp_ST3: transfer-property=PENDING
  pdu PT4_PTCoor4_ST3: length=4, minimum-delay=0.01, unused-bit-pattern=255
    signal CRC_PT4_PTCoor4_Pr5_ST3: start 0, 16 bit, little-endian, data-type-policy=OVERRIDE, i-signal-type=PRIMITIVE, base-type=uint16, range raw 0..65535 "16_CRC_w/oSNA_ImportedAdaptivePilot", transfer-property=PENDING, to ECU7_ExecutionContext1  # CRC-checksum of signal group according to AUTOSAR Profile 5
    signal SQC_PT4_PTCoor4_Pr5_ST3: start 16, 8 bit, little-endian, data-type-policy=OVERRIDE, i-signal-type=PRIMITIVE, base-type=uint8, compu {identical}, range raw 0..255 "08_0-255_1_SNA=-", transfer-property=PENDING, to ECU7_ExecutionContext1  # Sequence counter
    signal PT4_PTCoor_PT_Rdy_ST3: start 24, 2 bit, little-endian, data-type-policy=OVERRIDE, i-signal-type=PRIMITIVE, base-type=uint8, invalid-value=3, compu {0=I_C02_PT_RDY_V2_PT_NOT_RDY (PT_NOT_RDY) (Powertrain is not ready), 1=I_C02_PT_RDY_V2_PT_RDY (PT_RDY) (Powertrain is ready), 3=I_C02_PT_RDY_V2_SNA (SNA) (SNA value from data type)} "Powertrain ready", range raw 0..3 "02_PT_Rdy_V2", transfer-property=PENDING, to ECU7_ExecutionContext1  # Powertrain ready
    signal PT4_PTCoor_SSA_EngSp_ST3: start 26, 2 bit, little-endian, data-type-policy=OVERRIDE, i-signal-type=PRIMITIVE, base-type=uint8, invalid-value=3, compu {1=I_C02_NDEF_FALSE_TRUE_ST3_FALSE (FALSE) (False), 2=I_C02_NDEF_FALSE_TRUE_ST3_TRUE (TRUE) (True), 3=I_C02_NDEF_FALSE_TRUE_ST3_SNA (SNA) (SNA value from data type)} "OLDNAME: st3_02_NDEF_FALSE_TRUE_SNA", range raw 1..3 "02_Ndef_False_True_ST3", transfer-property=PENDING, to ECU7_ExecutionContext1  # Stop/start automatic has engine stopped
    signal PT4_PTCoor_EngStartPN14_Stat_ST3: start 28, 3 bit, little-endian, data-type-policy=OVERRIDE, i-signal-type=PRIMITIVE, base-type=uint8, invalid-value=7, compu {0=I_C03_ENGSTARTPN14_STAT_NO_COMBUSTIONSTART_RQ (NO_COMBUSTIONSTART_RQ) (No combustion start required), 1=I_C03_ENGSTARTPN14_STAT_CUSTOMER_START_RQ (CUSTOMER_START_RQ) (Customer start required), 2=I_C03_ENGSTARTPN14_STAT_AUTO_START_NO_PN_SUP_RQ (AUTO_START_NO_PN_SUP_RQ) (Automatic start without Powernet support required), 3=I_C03_ENGSTARTPN14_STAT_AUTO_START_PN_SUP_RQ (AUTO_START_PN_SUP_RQ) (Automatic start with Powernet support required), 7=I_C03_ENGSTARTPN14_STAT_SNA (SNA) (SNA value from data type)}, range raw 0..7 "03_EngStartPN14_Stat_ST3", transfer-property=TRIGGERED-ON-CHANGE, to ECU7_ExecutionContext1  # PT4 Engine Start PN14 State
    signal Rsrv1_PT4_PTCoor_PT_Rdy_Pr5_ST3: start 31, 1 bit, little-endian, data-type-policy=OVERRIDE, i-signal-type=PRIMITIVE, base-type=uint8, range raw 0..1, transfer-property=PENDING, to ECU7_ExecutionContext1  # Reserved for future use
  pdu pduCOMP_SOMEIP_UDP_E2E_Pr6_Event_P_COMP_SOMEIP_UDP_E2E_Pr6_Service_R_COMP_SOMEIP_UDP_E2E_Pr6_Service: length=17
    signal COMP_SOMEIP_UDP_E2E_Pr6_Event_P_COMP_SOMEIP_UDP_E2E_Pr6_Service_R_COMP_SOMEIP_UDP_E2E_Pr6_Service: start 0, to ECU7_ExecutionContext1
  pdu pduCOMP_SOMEIP_UDP_E2E_Pr7_Event_P_COMP_SOMEIP_UDP_E2E_Pr7_Service_R_COMP_SOMEIP_UDP_E2E_Pr7_Service: length=32
    signal COMP_SOMEIP_UDP_E2E_Pr7_Event_P_COMP_SOMEIP_UDP_E2E_Pr7_Service_R_COMP_SOMEIP_UDP_E2E_Pr7_Service: start 0, to ECU7_ExecutionContext1
  pdu pduCOMP_SOMEIP_UDP_Event_P_COMP_SOMEIP_UDP_Service_R_COMP_SOMEIP_UDP_Service: length=12
    signal COMP_SOMEIP_UDP_Event_P_COMP_SOMEIP_UDP_Service_R_COMP_SOMEIP_UDP_Service: start 0, to ECU7_ExecutionContext1
  pdu pduCOMP_SOMEIP_UDP_Method_NONE_P_COMP_SOMEIP_UDP_Service_R_COMP_SOMEIP_UDP_Service_return: length=8
    signal COMP_SOMEIP_UDP_Method_NONE_P_COMP_SOMEIP_UDP_Service_R_COMP_SOMEIP_UDP_Service_return: start 0, to ECU7_ExecutionContext1
  pdu pduCOMP_SOMEIP_UDP_Method_NONE_R_COMP_SOMEIP_UDP_Service_P_COMP_SOMEIP_UDP_Service_call: length=12
    signal COMP_SOMEIP_UDP_Method_NONE_R_COMP_SOMEIP_UDP_Service_P_COMP_SOMEIP_UDP_Service_call: start 0
  pdu pduECU7_SOMEIP_UDP_E2E_Pr6_Event_P_ECU7_SOMEIP_UDP_E2E_Pr6_Service_R_ECU7_SOMEIP_UDP_E2E_Pr6_Service: length=17
    signal ECU7_SOMEIP_UDP_E2E_Pr6_Event_P_ECU7_SOMEIP_UDP_E2E_Pr6_Service_R_ECU7_SOMEIP_UDP_E2E_Pr6_Service: start 0
  pdu pduECU7_SOMEIP_UDP_E2E_Pr7_Event_P_ECU7_SOMEIP_UDP_E2E_Pr7_Service_R_ECU7_SOMEIP_UDP_E2E_Pr7_Service: length=32
    signal ECU7_SOMEIP_UDP_E2E_Pr7_Event_P_ECU7_SOMEIP_UDP_E2E_Pr7_Service_R_ECU7_SOMEIP_UDP_E2E_Pr7_Service: start 0
  pdu pduECU7_SOMEIP_UDP_Event_P_ECU7_SOMEIP_UDP_Service_R_ECU7_SOMEIP_UDP_Service: length=12
    signal ECU7_SOMEIP_UDP_Event_P_ECU7_SOMEIP_UDP_Service_R_ECU7_SOMEIP_UDP_Service: start 0
  pdu pduECU7_SOMEIP_UDP_Method_NONE_P_ECU7_SOMEIP_UDP_Service_R_ECU7_SOMEIP_UDP_Service_return: length=8
    signal ECU7_SOMEIP_UDP_Method_NONE_P_ECU7_SOMEIP_UDP_Service_R_ECU7_SOMEIP_UDP_Service_return: start 0
  pdu pduECU7_SOMEIP_UDP_Method_NONE_R_ECU7_SOMEIP_UDP_Service_P_ECU7_SOMEIP_UDP_Service_call: length=12
    signal ECU7_SOMEIP_UDP_Method_NONE_R_ECU7_SOMEIP_UDP_Service_P_ECU7_SOMEIP_UDP_Service_call: start 0, to ECU7_ExecutionContext1
  pdu pduECU7_basicIPC_Event_P_ECU7_basicIPC_Service_R_ECU7_basicIPC_Service: length=1400
    signal ECU7_basicIPC_Event_P_ECU7_basicIPC_Service_R_ECU7_basicIPC_Service: start 0, to ECU7_ExecutionContext1
package /Communication/Signals
  i signal group DI_Odo_Pr5_ST3: i-signal=[CRC_DI_Odo_Pr5_ST3, Odo_ST3, SQC_DI_Odo_Pr5_ST3], system-signal-group=DI_Odo_Pr5_ST3  # DriverInformation Odometer
  i signal group Ign_Stat_Pr5_ST3: i-signal=[CRC_Ign_Stat_Pr5_ST3, ISw_Stat_ST3, KG_StartSw_Psd_ST3, SQC_Ign_Stat_Pr5_ST3, Veh_Op_Mode_ST3], system-signal-group=Ign_Stat_Pr5_ST3  # Ignition state
  i signal group PT4_PTCoor4_Pr5_ST3: i-signal=[CRC_PT4_PTCoor4_Pr5_ST3, PT4_PTCoor_EngStartPN14_Stat_ST3, PT4_PTCoor_PT_Rdy_ST3, PT4_PTCoor_SSA_EngSp_ST3, Rsrv1_PT4_PTCoor_PT_Rdy_Pr5_ST3, SQC_PT4_PTCoor4_Pr5_ST3], system-signal-group=PT4_PTCoor4_Pr5_ST3
package /Communication/SystemSignalGroups
  system signal group DI_Odo_Pr5_ST3: system-signal=[CRC_DI_Odo_Pr5_ST3, Odo_ST3, SQC_DI_Odo_Pr5_ST3]  # DriverInformation Odometer
  system signal group Ign_Stat_Pr5_ST3: system-signal=[CRC_Ign_Stat_Pr5_ST3, ISw_Stat_ST3, KG_StartSw_Psd_ST3, SQC_Ign_Stat_Pr5_ST3, Veh_Op_Mode_ST3]  # Ignition state
package /DataConstraints
  range c08_0_255_1_SNA_na: phys 0..255  # 08_0-255_1_SNA=-
  range c08_0_255_1_SNA_na2: raw 0..255  # 08_0-255_1_SNA=-
  range c08_0_255_1_SNA_na4: phys 0..255  # 08_0-255_1_SNA=-
  range c10_V_0_25k55_0k0251: raw 0..1023  # 10_V_0-25,55_0,025
  range c12_0_4094_1_SNA1: raw 0..4095  # 12_0-4094_1_SNA
  range c24_km_0_999999k9_0k1_Invld_SNA1: raw 0..16777215  # 24_km_0-999999,9_0,1_Invld_SNA
package /DataTypes/ImplementationDataTypes
  13 x std cpp implementation data type:
    ARR_Uint32_348: category=ARRAY, array-size=348, cpp-template-argument{category=VALUE, template-type=uint32_t}, type-emitter=TYPE_EMITTER_ARA
      namespaces:
        4 x symbol props:
          daimler
          cppDataTypes
          common
          NS_ARR_Uint32_348
    REC_DI_Odo_Pr5_ST3: category=STRUCTURE, type-emitter=TYPE_EMITTER_ARA
      namespaces:
        4 x symbol props:
          daimler
          cppDataTypes
          common
          NS_REC_DI_Odo_Pr5_ST3
      cpp implementation data type element CRC_DI_Odo_Pr5_ST3: is-optional=false, type-reference=uint16_t
      cpp implementation data type element Odo_ST3: is-optional=false, type-reference=uint32_t
      cpp implementation data type element SQC_DI_Odo_Pr5_ST3: is-optional=false, type-reference=uint8_t
    REC_Ign_Stat_Pr5_ST3: category=STRUCTURE, type-emitter=TYPE_EMITTER_ARA
      namespaces:
        4 x symbol props:
          daimler
          cppDataTypes
          common
          NS_REC_Ign_Stat_Pr5_ST3
      5 x cpp implementation data type element, all with is-optional=false:
        ISw_Stat_ST3: type-reference=uint8_t
        Veh_Op_Mode_ST3: type-reference=uint8_t
        CRC_Ign_Stat_Pr5_ST3: type-reference=uint16_t
        SQC_Ign_Stat_Pr5_ST3: type-reference=uint8_t
        KG_StartSw_Psd_ST3: type-reference=bool
    REC_PT4_PTCoor4_Pr5_ST3: category=STRUCTURE, type-emitter=TYPE_EMITTER_ARA
      namespaces:
        4 x symbol props:
          daimler
          cppDataTypes
          common
          NS_REC_PT4_PTCoor4_Pr5_ST3
      6 x cpp implementation data type element, all with is-optional=false:
        CRC_PT4_PTCoor4_Pr5_ST3: type-reference=uint16_t
        PT4_PTCoor_PT_Rdy_ST3: type-reference=uint8_t
        SQC_PT4_PTCoor4_Pr5_ST3: type-reference=uint8_t
        PT4_PTCoor_EngStartPN14_Stat_ST3: type-reference=uint8_t
        PT4_PTCoor_SSA_EngSp_ST3: type-reference=uint8_t
        Rsrv1_PT4_PTCoor_PT_Rdy_Pr5_ST3: type-reference=uint8_t
    REC_TestSerialized_AdAR: category=STRUCTURE, type-emitter=TYPE_EMITTER_ARA
      namespaces:
        4 x symbol props:
          daimler
          cppDataTypes
          common
          NS_REC_TestSerialized_AdAR
      cpp implementation data type element ActualClientID: is-optional=false, type-reference=uint16_t
      cpp implementation data type element TestSig: is-optional=false, type-reference=uint8_t
      cpp implementation data type element ErrorStatus: is-optional=false, type-reference=uint8_t
    bool: category=VALUE
    uint16_t: category=VALUE, type-emitter=cstdint
    uint32_t: category=VALUE, type-emitter=cstdint
    uint8_t: category=VALUE, type-emitter=cstdint
    string: category=STRING, type-emitter=TYPE_EMITTER_ARA
      namespaces:
        symbol props ara
        symbol props diag
    uint64_t: category=VALUE, type-emitter=cstdint  # unsigned integer 64bit
    REC_ECU_Stat_ECU7_ST3: category=STRUCTURE, type-emitter=TYPE_EMITTER_ARA
      namespaces:
        4 x symbol props:
          daimler
          cppDataTypes
          common
          NS_REC_ECU_Stat_ECU7_ST3
      6 x cpp implementation data type element, all with is-optional=false:
        ECU_Id_ECU7_ST3: type-reference=uint16_t
        WakeupRsn_ECU7_ST3: type-reference=uint16_t
        Awake_Diag_Actv_ECU7_ST3: type-reference=bool
        Awake_NwStart_ECU7_ST3: type-reference=bool
        Awake_Ignition_On_ECU7_ST3: type-reference=bool
        Awake_HAD_Actv_ECU7_ST3: type-reference=bool
    REC_PN14_Master_Stat1_ST3: category=STRUCTURE, type-emitter=TYPE_EMITTER_ARA
      namespaces:
        4 x symbol props:
          daimler
          cppDataTypes
          common
          NS_REC_PN14_Master_Stat1_ST3
      cpp implementation data type element PN14_ProdMd_Stat_ST3: is-optional=false, type-reference=uint8_t
      cpp implementation data type element PN14_SupBat_Volt_ST3: is-optional=false, type-reference=uint16_t
      cpp implementation data type element PN14_TransMd_Stat_ST3: is-optional=false, type-reference=uint8_t
package /DataTypes/ModelManagement
  mode declaration group MachineStates: initial-mode=Startup
    5 x mode:
      Off: value=4
      Restart: value=3
      Shutdown: value=2
      Startup: value=1
      Running: value=0
package /DataTypes/Units
  unit NoUnit: display-name=NoUnit
  unit V: display-name=V
  unit km: display-name=km
package /E2EProfileConfigurationSet
  e 2 e profile configuration set End2EndProps
    e 2 e profile configuration E2E_Profile_6: max-delta-counter=3, max-error-state-init=0, max-error-state-invalid=0, max-error-state-valid=0, min-ok-state-init=1, min-ok-state-invalid=1, min-ok-state-valid=1, profile-name=PROFILE_06, window-size=10
    e 2 e profile configuration E2E_Profile_7: max-delta-counter=3, max-error-state-init=0, max-error-state-invalid=0, max-error-state-valid=0, min-ok-state-init=1, min-ok-state-invalid=1, min-ok-state-valid=1, profile-name=PROFILE_07, window-size=10
package /Machine
  machine ECU7_CTP_Cluster: machine-design=ECU7_ExecutionContext1
    function-groups:
      mode declaration group prototype ECU7_ModeDeclarationGroupElement: type=MachineStates
      mode declaration group prototype MachineState: type=MachineStates
    processor ECU7_Microprocessor
      processor core ECU7_Core0: core-id=0
package /Machine/ProcessToMachineMappings
  process to machine mapping set SW_to_HW_Mappings
    6 x process to machine mapping, all with machine=ECU7_CTP_Cluster:
      Application_S2S_Process_To_ECU7_CTP_Cluster_Mapping: process=Application_S2S_Process, shall-run-on=ECU7_Core0
      Application_SOMEIP_Process_To_ECU7_CTP_Cluster_Mapping: process=Application_SOMEIP_Process, shall-run-on=ECU7_Core0
      Application_basicIPC1_Process_To_ECU7_CTP_Cluster_Mapping: process=Application_basicIPC1_Process, shall-run-on=ECU7_Core0
      Application_basicIPC2_Process_To_ECU7_CTP_Cluster_Mapping: process=Application_basicIPC2_Process, shall-run-on=ECU7_Core0
      SelfDiagnosticAgent_Process_To_ECU7_CTP_Cluster_Mapping: process=SelfDiagnosticAgent_Process, shall-run-on=ECU7_Core0
      DiagnosticManager_IDC6_M: process=DiagnosticManagerDeamon
package /Machine/StartupConfigSets
  startup config set startupConfig
    startup config STARTUP_CONFIG_DEFAULT: scheduling-policy=SCHEDULING-POLICY-ROUND-ROBIN, scheduling-priority=20, startup-option{option-argument=./etc/application.json, option-kind=COMMAND-LINE-SHORT-FORM, option-name=c}
package /ServiceInstances
  4 x provided someip service instance:
    PSI_ECU_Stat_ECU7_Service_ST3: service-interface=SomeIpECU_Stat_ECU7_Service_ST3, someip-event-props=event=SomeIpECU_Stat_ECU7_ST3, sd-server-config=ServerSd_PSI_ECU_Stat_ECU7_Service_ST3, service-instance-id=1
      someip provided event group SomeIpECU_STAT: event-group=ECU_STAT, multicast-threshold=7, sd-server-event-group-timing-config=ServerEgSd_SomeIpECU_STAT
    PSI_SomeIp_ECU7_SOMEIP_UDP_E2E_Pr6_Service: service-interface=SomeIpECU7_SOMEIP_UDP_E2E_Pr6_Service, someip-event-props=event=SomeIpECU7_SOMEIP_UDP_E2E_Pr6_Event, sd-server-config=ServerSd_PSI_SomeIp_ECU7_SOMEIP_UDP_E2E_Pr6_Service, service-instance-id=10
      e-2-e-event-protection-propss:
        end 2 end event protection props E2E_Pr6_ECU7_SOMEIP_UDP_E2E_Pr6_Event_Tx: data-ids=189, e-2-e-profile-configuration=E2E_Profile_6, event=SomeIpECU7_SOMEIP_UDP_E2E_Pr6_Event, max-data-length=136, min-data-length=136
      someip provided event group SomeIpECU7_SOMEIP_UDP_E2E_Pr7_Event: event-group=SomeIpECU7_SOMEIP_UDP_E2E_Pr6_Service/ECU7_SOMEIP_UDP_E2E_Pr7_Event, multicast-threshold=5, sd-server-event-group-timing-config=ServerEgSd_SomeIpECU7_SOMEIP_UDP_E2E_Pr7_Event1
    PSI_SomeIp_ECU7_SOMEIP_UDP_E2E_Pr7_Service: service-interface=SomeIpECU7_SOMEIP_UDP_E2E_Pr7_Service, someip-event-props=event=SomeIpECU7_SOMEIP_UDP_E2E_Pr7_Event, sd-server-config=ServerSd_PSI_SomeIp_ECU7_SOMEIP_UDP_E2E_Pr7_Service, service-instance-id=10
      e-2-e-event-protection-propss:
        end 2 end event protection props E2E_Pr7_ECU7_SOMEIP_UDP_E2E_Pr7_Event_Tx: data-ids=3, e-2-e-profile-configuration=E2E_Profile_7, event=SomeIpECU7_SOMEIP_UDP_E2E_Pr7_Event, max-data-length=256, min-data-length=256
      someip provided event group SomeIpECU7_SOMEIP_UDP_E2E_Pr7_Event: event-group=SomeIpECU7_SOMEIP_UDP_E2E_Pr7_Service/ECU7_SOMEIP_UDP_E2E_Pr7_Event, multicast-threshold=5, sd-server-event-group-timing-config=ServerEgSd_SomeIpECU7_SOMEIP_UDP_E2E_Pr7_Event
    PSI_SomeIp_ECU7_SOMEIP_UDP_Service: service-interface=SomeIpECU7_SOMEIP_UDP_Service, someip-event-props=event=SomeIpECU7_SOMEIP_UDP_Event, someip-method-props=method=SomeIpECU7_SOMEIP_UDP_Method, sd-server-config=ServerSd_PSI_SomeIp_ECU7_SOMEIP_UDP_Service, service-instance-id=10
      someip provided event group SomeIpECU7_SOMEIP_UDP_Event: event-group=ECU7_SOMEIP_UDP_Event, multicast-threshold=5, sd-server-event-group-timing-config=ServerEgSd_SomeIpECU7_SOMEIP_UDP_Event
  provided user defined service instance PSI_UD_ECU7_basicIPC_Service: service-interface=UD_ECU7_basicIPC_Service
  provided user defined service instance SelfDiagAgent_ProvidedBindingServiceInstance_DiagComApi: service-interface=DiagComApi_Binding
  8 x required someip service instance, all with required-minor-version=0:
    CSI_DI_OdoSpeedometer_Service_ST3: service-interface=SomeIpDI_OdoSpeedometer_Service_ST3, required-service-instance-id=1, sd-client-config=ClientSd_CSI_DI_OdoSpeedometer_Service_ST3
      someip required event group SomeIpDI_Master_Odometer: event-group=DI_Master_Odometer, sd-client-event-group-timing-config=ClientEgSd_SomeIpDI_Master_Odometer
    CSI_Immobilizer_Master_Service_ST3: service-interface=SomeIpImmobilizer_Master_Service_ST3, required-service-instance-id=1, sd-client-config=ClientSd_CSI_Immobilizer_Master_Service_ST3
      someip required event group SomeIpIgn_Stat: event-group=Ign_Stat, sd-client-event-group-timing-config=ClientEgSd_SomeIpIgn_Stat
    CSI_PN14_Master_Service_ST3: service-interface=SomeIpPN14_Master_Service_ST3, required-service-instance-id=1, sd-client-config=ClientSd_CSI_PN14_Master_Service_ST3
      someip required event group SomeIpPN14_Master: event-group=PN14_Master, sd-client-event-group-timing-config=ClientEgSd_SomeIpPN14_Master
    CSI_PT4_PTCoor_Service_ST3: service-interface=SomeIpPT4_PTCoor_Service_ST3, required-service-instance-id=1, sd-client-config=ClientSd_CSI_PT4_PTCoor_Service_ST3
      someip required event group SomeIpPT4_PTCoor4: event-group=PT4_PTCoor4, sd-client-event-group-timing-config=ClientEgSd_SomeIpPT4_PTCoor4
    CSI_SomeIp_COMP_SOMEIP_UDP_E2E_Pr6_Service: service-interface=SomeIpCOMP_SOMEIP_UDP_E2E_Pr6_Service, required-service-instance-id=10, sd-client-config=ClientSd_CSI_SomeIp_COMP_SOMEIP_UDP_E2E_Pr6_Service
      e-2-e-event-protection-propss:
        end 2 end event protection props E2E_Pr6_COMP_SOMEIP_UDP_E2E_Pr6_Event_Rx: data-ids=191, e-2-e-profile-configuration=E2E_Profile_6, event=SomeIpCOMP_SOMEIP_UDP_E2E_Pr6_Event, max-data-length=136, min-data-length=136
      someip required event group SomeIpCOMP_SOMEIP_UDP_E2E_Pr6_Event: event-group=COMP_SOMEIP_UDP_E2E_Pr6_Event, sd-client-event-group-timing-config=ClientEgSd_SomeIpCOMP_SOMEIP_UDP_E2E_Pr6_Event
    CSI_SomeIp_COMP_SOMEIP_UDP_E2E_Pr7_Service: service-interface=SomeIpCOMP_SOMEIP_UDP_E2E_Pr7_Service, required-service-instance-id=10, sd-client-config=ClientSd_CSI_SomeIp_COMP_SOMEIP_UDP_E2E_Pr7_Service
      e-2-e-event-protection-propss:
        end 2 end event protection props E2E_Pr7_COMP_SOMEIP_UDP_E2E_Pr7_Event_Rx: data-ids=4, e-2-e-profile-configuration=E2E_Profile_7, event=SomeIpCOMP_SOMEIP_UDP_E2E_Pr7_Event, max-data-length=256, min-data-length=256
      someip required event group SomeIpCOMP_SOMEIP_UDP_E2E_Pr7_Event: event-group=COMP_SOMEIP_UDP_E2E_Pr7_Event, sd-client-event-group-timing-config=ClientEgSd_SomeIpCOMP_SOMEIP_UDP_E2E_Pr7_Event
    CSI_SomeIp_COMP_SOMEIP_UDP_Service: service-interface=SomeIpCOMP_SOMEIP_UDP_Service, someip-method-props=method=SomeIpCOMP_SOMEIP_UDP_Method, required-service-instance-id=10, sd-client-config=ClientSd_CSI_SomeIp_COMP_SOMEIP_UDP_Service
      someip required event group SomeIpCOMP_SOMEIP_UDP_Event: event-group=COMP_SOMEIP_UDP_Event, sd-client-event-group-timing-config=ClientEgSd_SomeIpCOMP_SOMEIP_UDP_Event
    CSI_SomeIp_ECU7_basicIPC_Service: service-interface=SomeIpECU7_basicIPC_Service, required-service-instance-id=10, sd-client-config=ClientSd_CSI_SomeIp_ECU7_basicIPC_Service
      someip required event group SomeIpECU7_basicIPC_Event: event-group=ECU7_basicIPC_Event, sd-client-event-group-timing-config=ClientEgSd_SomeIpECU7_basicIPC_Event
  required user defined service instance CSI_UD_ECU7_basicIPC_Service: service-interface=UD_ECU7_basicIPC_Service
  required user defined service instance DiagnosticManager_RequiredBindingServiceInstance_DiagComApi: service-interface=DiagComApi_Binding
  required user defined service instance DiagnosticManager_SWUC_RequiredBindingServiceInstance_DiagComApi: service-interface=DiagComApi_Binding
package /ServiceInstances/ServiceInstanceToMachineMappings
  12 x someip service instance to machine mapping, all with udp-port=40000:
    COMP_SOMEIP_UDP_E2E_Pr6_Service_ECU7_ExecutionContext1_BusSystem20Mapping: communication-connector=EthernetECUInterface_ECU7_ExecutionContext1, service-instance=CSI_SomeIp_COMP_SOMEIP_UDP_E2E_Pr6_Service
    COMP_SOMEIP_UDP_E2E_Pr7_Service_ECU7_ExecutionContext1_BusSystem20Mapping: communication-connector=EthernetECUInterface_ECU7_ExecutionContext1, service-instance=CSI_SomeIp_COMP_SOMEIP_UDP_E2E_Pr7_Service
    COMP_SOMEIP_UDP_Service_ECU7_ExecutionContext1_BusSystem20Mapping: communication-connector=EthernetECUInterface_ECU7_ExecutionContext1, service-instance=CSI_SomeIp_COMP_SOMEIP_UDP_Service
    DI_OdoSpeedometer_Service_ST3_EthernetECUInterface_ECU7_ExecutionContext1Mapping: communication-connector=EthernetECUInterface_ECU7_ExecutionContext1, service-instance=CSI_DI_OdoSpeedometer_Service_ST3
    ECU7_SOMEIP_UDP_E2E_Pr6_Service_ECU7_ExecutionContext1_BusSystem20Mapping: communication-connector=EthernetECUInterface_ECU7_ExecutionContext1, service-instance=PSI_SomeIp_ECU7_SOMEIP_UDP_E2E_Pr6_Service
    ECU7_SOMEIP_UDP_E2E_Pr7_Service_ECU7_ExecutionContext1_BusSystem20Mapping: communication-connector=EthernetECUInterface_ECU7_ExecutionContext1, service-instance=PSI_SomeIp_ECU7_SOMEIP_UDP_E2E_Pr7_Service
    ECU7_SOMEIP_UDP_Service_ECU7_ExecutionContext1_BusSystem20Mapping: communication-connector=EthernetECUInterface_ECU7_ExecutionContext1, service-instance=PSI_SomeIp_ECU7_SOMEIP_UDP_Service
    ECU7_basicIPC_Service_ECU7_ExecutionContext1_BusSystem20Mapping: communication-connector=EthernetECUInterface_ECU7_ExecutionContext1, service-instance=CSI_SomeIp_ECU7_basicIPC_Service
    ECU_Stat_ECU7_Service_ST3_ECU7_ExecutionContext1_BusSystem20Mapping: communication-connector=ECU7_ExecutionContext1_BusSystem20, service-instance=PSI_ECU_Stat_ECU7_Service_ST3
    Immobilizer_Master_Service_ST3_EthernetECUInterface_ECU7_ExecutionContext1Mapping: communication-connector=EthernetECUInterface_ECU7_ExecutionContext1, service-instance=CSI_Immobilizer_Master_Service_ST3
    PN14_Master_Service_ST3_EthernetECUInterface_ECU7_ExecutionContext1Mapping: communication-connector=EthernetECUInterface_ECU7_ExecutionContext1, service-instance=CSI_PN14_Master_Service_ST3
    PT4_PTCoor_Service_ST3_EthernetECUInterface_ECU7_ExecutionContext1Mapping: communication-connector=EthernetECUInterface_ECU7_ExecutionContext1, service-instance=CSI_PT4_PTCoor_Service_ST3
package /ServiceInstances/ServiceInstanceToPortPrototypeMappings
  21 x service instance to port prototype mapping:
    CSI_DI_OdoSpeedometer_Service_ST3_Application_S2S_PortPrototypeMapping: port-prototype=Application_S2S_ExecutableRootSwc.R_DI_OdoSpeedometer_Service_ST3, process=Application_S2S_Process, service-instance=CSI_DI_OdoSpeedometer_Service_ST3
    CSI_DI_OdoSpeedometer_Service_ST3_SelfDiagnosticAgent_PortPrototypeMapping: port-prototype=SelfDiagnosticAgent_ExecutableRootSwc.R_DI_OdoSpeedometer_Service_ST3, process=SelfDiagnosticAgent_Process, service-instance=CSI_DI_OdoSpeedometer_Service_ST3
    CSI_Immobilizer_Master_Service_ST3_Application_S2S_PortPrototypeMapping: port-prototype=Application_S2S_ExecutableRootSwc.R_Immobilizer_Service_ST3, process=Application_S2S_Process, service-instance=CSI_Immobilizer_Master_Service_ST3
    CSI_Immobilizer_Master_Service_ST3_SelfDiagnosticAgent_PortPrototypeMapping: port-prototype=SelfDiagnosticAgent_ExecutableRootSwc.R_Immobilizer_Service_ST3, process=SelfDiagnosticAgent_Process, service-instance=CSI_Immobilizer_Master_Service_ST3
    CSI_PN14_Master_Service_ST3_Application_S2S_PortPrototypeMapping: port-prototype=Application_S2S_ExecutableRootSwc.R_PN14_Master_Service_ST3, process=Application_S2S_Process, service-instance=CSI_PN14_Master_Service_ST3
    CSI_PN14_Master_Service_ST3_SelfDiagnosticAgent_PortPrototypeMapping: port-prototype=SelfDiagnosticAgent_ExecutableRootSwc.R_PN14_Master_Service_ST3, process=SelfDiagnosticAgent_Process, service-instance=CSI_PN14_Master_Service_ST3
    CSI_PT4_PTCoor_Service_ST3_Application_S2S_PortPrototypeMapping: port-prototype=Application_S2S_ExecutableRootSwc.R_PT4_PTCoor_Service_ST3, process=Application_S2S_Process, service-instance=CSI_PT4_PTCoor_Service_ST3
    CSI_PT4_PTCoor_Service_ST3_SelfDiagnosticAgent_PortPrototypeMapping: port-prototype=SelfDiagnosticAgent_ExecutableRootSwc.R_PT4_PTCoor_Service_ST3, process=SelfDiagnosticAgent_Process, service-instance=CSI_PT4_PTCoor_Service_ST3
    CSI_SomeIp_COMP_SOMEIP_UDP_E2E_Pr6_Service_Application_SOMEIP_PortPrototypeMapping: port-prototype=Application_SOMEIP_ExecutableRootSwc.R_COMP_SOMEIP_UDP_E2E_Pr6_Service, process=Application_SOMEIP_Process, service-instance=CSI_SomeIp_COMP_SOMEIP_UDP_E2E_Pr6_Service
    CSI_SomeIp_COMP_SOMEIP_UDP_E2E_Pr7_Service_Application_SOMEIP_PortPrototypeMapping: port-prototype=Application_SOMEIP_ExecutableRootSwc.R_COMP_SOMEIP_UDP_E2E_Pr7_Service, process=Application_SOMEIP_Process, service-instance=CSI_SomeIp_COMP_SOMEIP_UDP_E2E_Pr7_Service
    CSI_SomeIp_COMP_SOMEIP_UDP_Service_Application_SOMEIP_PortPrototypeMapping: port-prototype=Application_SOMEIP_ExecutableRootSwc.R_COMP_SOMEIP_UDP_Service, process=Application_SOMEIP_Process, service-instance=CSI_SomeIp_COMP_SOMEIP_UDP_Service
    CSI_SomeIp_ECU7_basicIPC_Service_Application_basicIPC1_PortPrototypeMapping: port-prototype=Application_basicIPC1_ExecutableRootSwc.R_ECU7_basicIPC_Service, process=Application_basicIPC1_Process, service-instance=CSI_SomeIp_ECU7_basicIPC_Service
    CSI_UD_ECU7_basicIPC_Service__Application_basicIPC2_PortPrototypeMapping: port-prototype=Application_basicIPC2_ExecutableRootSwc.R_ECU7_basicIPC_Service, process=Application_basicIPC2_Process, service-instance=CSI_UD_ECU7_basicIPC_Service
    PSI_ECU_Stat_ECU7_Service_ST3_Application_S2S_PortPrototypeMapping: port-prototype=Application_S2S_ExecutableRootSwc.P_ECU_Stat_ECU7_Service_ST3, process=Application_S2S_Process, service-instance=PSI_ECU_Stat_ECU7_Service_ST3
    PSI_SomeIp_ECU7_SOMEIP_UDP_E2E_Pr6_Service_Application_SOMEIP_PortPrototypeMapping: port-prototype=Application_SOMEIP_ExecutableRootSwc.P_ECU7_SOMEIP_UDP_E2E_Pr6_Service, process=Application_SOMEIP_Process, service-instance=PSI_SomeIp_ECU7_SOMEIP_UDP_E2E_Pr6_Service
    PSI_SomeIp_ECU7_SOMEIP_UDP_E2E_Pr7_Service_Application_SOMEIP_PortPrototypeMapping: port-prototype=Application_SOMEIP_ExecutableRootSwc.P_ECU7_SOMEIP_UDP_E2E_Pr7_Service, process=Application_SOMEIP_Process, service-instance=PSI_SomeIp_ECU7_SOMEIP_UDP_E2E_Pr7_Service
    PSI_SomeIp_ECU7_SOMEIP_UDP_Service_Application_SOMEIP_PortPrototypeMapping: port-prototype=Application_SOMEIP_ExecutableRootSwc.P_ECU7_SOMEIP_UDP_Service, process=Application_SOMEIP_Process, service-instance=PSI_SomeIp_ECU7_SOMEIP_UDP_Service
    PSI_UD_ECU7_basicIPC_Service__Application_basicIPC1_PortPrototypeMapping: port-prototype=Application_basicIPC1_ExecutableRootSwc.P_ECU7_basicIPC_Service, process=Application_basicIPC1_Process, service-instance=PSI_UD_ECU7_basicIPC_Service
    SelfDiagAgent_ProvidedBindingServiceInstance_DiagComApi_toPort: port-prototype=SelfDiagnosticAgent_ExecutableRootSwc.amsr_DiagComApi, process=SelfDiagnosticAgent_Process, service-instance=SelfDiagAgent_ProvidedBindingServiceInstance_DiagComApi
    SelfDiagAgent_RequiredBindingServiceInstance_DiagComApi_toPort: port-prototype=DiagnosticManagerDeamonExecutableRootSwc.DiagComApiDeamonPort, process=DiagnosticManagerDeamon, service-instance=DiagnosticManager_RequiredBindingServiceInstance_DiagComApi
    SWUC_RequiredBindingServiceInstance_DiagComApi_toPort: port-prototype=DiagnosticManagerDeamonExecutableRootSwc.DiagComApiDeamonPort, process=DiagnosticManagerDeamon, service-instance=DiagnosticManager_SWUC_RequiredBindingServiceInstance_DiagComApi
package /ServiceInstances/ServiceInstanceToSignalMappingSets
  5 x service instance to signal mapping set:
    CSI_DI_OdoSpeedometer_Service_ST3_MappingSet
      service instance to signal mapping CSI_DI_OdoSpeedometer_Service_ST3_DI_OdoSpeedometer_ST3: signal-based-event-element-to-i-signal-triggering-mapping{data-prototype-in-service-interface=element-in-impl-datatype={root-data-prototype=DI_OdoSpeedometer_ST3, target-data-prototype=Odo_ST3}, i-signal-triggering=Odo_ST3_d6g4rtn2fbvnvuedb1bthoaa7}, service-instance=CSI_DI_OdoSpeedometer_Service_ST3
    CSI_Immobilizer_Master_Service_ST3_MappingSet
      service instance to signal mapping CSI_Immobilizer_Master_Service_ST3_Ign_Stat_ST3: service-instance=CSI_Immobilizer_Master_Service_ST3
        event-element-mappings:
          {data-prototype-in-service-interface=element-in-impl-datatype={root-data-prototype=Ign_Stat_ST3, target-data-prototype=ISw_Stat_ST3}, i-signal-triggering=ISw_Stat_ST3_cwdf0eh2o1gg213w41cxb5k6r}
          {data-prototype-in-service-interface=element-in-impl-datatype={root-data-prototype=Ign_Stat_ST3, target-data-prototype=KG_StartSw_Psd_ST3}, i-signal-triggering=KG_StartSw_Psd_ST3_ahpn9rvp2s3llwf7xzpoxwb4r}
          {data-prototype-in-service-interface=element-in-impl-datatype={root-data-prototype=Ign_Stat_ST3, target-data-prototype=Veh_Op_Mode_ST3}, i-signal-triggering=Veh_Op_Mode_ST3_29sefiepoa6hu1tehe5a6hmfn}
    CSI_PN14_Master_Service_ST3_MappingSet
      service instance to signal mapping CSI_PN14_Master_Service_ST3_PN14_Master_Stat1_ST3: service-instance=CSI_PN14_Master_Service_ST3
        event-element-mappings:
          {data-prototype-in-service-interface=element-in-impl-datatype={root-data-prototype=PN14_Master_Stat1_ST3, target-data-prototype=PN14_ProdMd_Stat_ST3}, i-signal-triggering=PN14_ProdMd_Stat_ST3_bkply6n5n6yxrkqr5f8iap745}
          {data-prototype-in-service-interface=element-in-impl-datatype={root-data-prototype=PN14_Master_Stat1_ST3, target-data-prototype=PN14_SupBat_Volt_ST3}, i-signal-triggering=PN14_SupBat_Volt_ST3_8u01chlhgjo76bq71u3p5itlo}
          {data-prototype-in-service-interface=element-in-impl-datatype={root-data-prototype=PN14_Master_Stat1_ST3, target-data-prototype=PN14_TransMd_Stat_ST3}, i-signal-triggering=PN14_TransMd_Stat_ST3_f5fxvx1gmpnq1xrns0t9mpe1y}
    CSI_PT4_PTCoor_Service_ST3_MappingSet
      service instance to signal mapping CSI_PT4_PTCoor_Service_ST3_PT4_PTCoor4_ST3: service-instance=CSI_PT4_PTCoor_Service_ST3
        event-element-mappings:
          {data-prototype-in-service-interface=element-in-impl-datatype={root-data-prototype=PT4_PTCoor4_ST3, target-data-prototype=PT4_PTCoor_EngStartPN14_Stat_ST3}, i-signal-triggering=PT4_PTCoor_EngStartPN14_Stat_ST3_1aq6rlo2m1p5814zhd9wcecd7}
          {data-prototype-in-service-interface=element-in-impl-datatype={root-data-prototype=PT4_PTCoor4_ST3, target-data-prototype=PT4_PTCoor_PT_Rdy_ST3}, i-signal-triggering=PT4_PTCoor_PT_Rdy_ST3_5xpspdp9z2fnud6sn29cuhnx5}
          {data-prototype-in-service-interface=element-in-impl-datatype={root-data-prototype=PT4_PTCoor4_ST3, target-data-prototype=PT4_PTCoor_SSA_EngSp_ST3}, i-signal-triggering=PT4_PTCoor_SSA_EngSp_ST3_807f7d5e8eg2ebimeqi8cwpsf}
          {data-prototype-in-service-interface=element-in-impl-datatype={root-data-prototype=PT4_PTCoor4_ST3, target-data-prototype=Rsrv1_PT4_PTCoor_PT_Rdy_Pr5_ST3}, i-signal-triggering=Rsrv1_PT4_PTCoor_PT_Rdy_Pr5_ST3_rujz5cunvb1vvbie7f4oyiz1}
    PSI_ECU_Stat_ECU7_Service_ST3_S2StestMapping
      service instance to signal mapping PSI_ECU_Stat_ECU7_Service_ST3_ECU_Stat_ECU7_ST3: service-instance=PSI_ECU_Stat_ECU7_Service_ST3
        event-element-mappings:
          {data-prototype-in-service-interface=element-in-impl-datatype={root-data-prototype=ECU_Stat_ECU7_ST3, target-data-prototype=Awake_Diag_Actv_ECU7_ST3}, i-signal-triggering=Awake_Diag_Actv_ECU7_ST3_67ea21bmckg7i7akp75fsnlbz}
          {data-prototype-in-service-interface=element-in-impl-datatype={root-data-prototype=ECU_Stat_ECU7_ST3, target-data-prototype=Awake_HAD_Actv_ECU7_ST3}, i-signal-triggering=Awake_HAD_Actv_ECU7_ST3_7s289plsihxrivdyc0r7qom5v}
          {data-prototype-in-service-interface=element-in-impl-datatype={root-data-prototype=ECU_Stat_ECU7_ST3, target-data-prototype=Awake_Ignition_On_ECU7_ST3}, i-signal-triggering=Awake_Ignition_On_ECU7_ST3_181yx3rsx5os143d1hrhtto96}
          {data-prototype-in-service-interface=element-in-impl-datatype={root-data-prototype=ECU_Stat_ECU7_ST3, target-data-prototype=Awake_NwStart_ECU7_ST3}, i-signal-triggering=Awake_NwStart_ECU7_ST3_bzj3diy456j515nqtzkp3icem}
          {data-prototype-in-service-interface=element-in-impl-datatype={root-data-prototype=ECU_Stat_ECU7_ST3, target-data-prototype=ECU_Id_ECU7_ST3}, i-signal-triggering=ECU_Id_ECU7_ST3_55u294y14xpc9v49jemddxm2y}
          {data-prototype-in-service-interface=element-in-impl-datatype={root-data-prototype=ECU_Stat_ECU7_ST3, target-data-prototype=WakeupRsn_ECU7_ST3}, i-signal-triggering=WakeupRsn_ECU7_ST3_r6r5hj5p2r3oa3v8pfnzkuni}
package /ServiceInstances/SomeipSdTimingConfigs
  8 x someip sd client event group timing config, all with time-to-live=16777215:
    ClientEgSd_SomeIpCOMP_SOMEIP_UDP_E2E_Pr6_Event: request-response-delay={max-value=0.02, min-value=0}
    ClientEgSd_SomeIpCOMP_SOMEIP_UDP_E2E_Pr7_Event: request-response-delay={max-value=0.02, min-value=0}
    ClientEgSd_SomeIpCOMP_SOMEIP_UDP_Event: request-response-delay={max-value=0.02, min-value=0}
    ClientEgSd_SomeIpDI_Master_Odometer: request-response-delay={max-value=0.02, min-value=0}
    ClientEgSd_SomeIpECU7_basicIPC_Event: request-response-delay={max-value=0.02, min-value=0}
    ClientEgSd_SomeIpIgn_Stat: request-response-delay={max-value=0.02, min-value=0}
    ClientEgSd_SomeIpPN14_Master: request-response-delay={max-value=0.02, min-value=0}
    ClientEgSd_SomeIpPT4_PTCoor4
  8 x someip sd client service instance config, all with service-find-time-to-live=16777215:
    ClientSd_CSI_DI_OdoSpeedometer_Service_ST3: initial-find-behavior={initial-delay-max-value=0.105, initial-delay-min-value=0.105, initial-repetitions-base-delay=0.04, initial-repetitions-max=9}
    ClientSd_CSI_Immobilizer_Master_Service_ST3: initial-find-behavior={initial-delay-max-value=0, initial-delay-min-value=0, initial-repetitions-base-delay=0.04, initial-repetitions-max=9}
    ClientSd_CSI_PN14_Master_Service_ST3: initial-find-behavior={initial-delay-max-value=0.015, initial-delay-min-value=0.015, initial-repetitions-base-delay=0.04, initial-repetitions-max=9}
    ClientSd_CSI_PT4_PTCoor_Service_ST3: initial-find-behavior={initial-delay-max-value=0.07, initial-delay-min-value=0.07, initial-repetitions-base-delay=0.04, initial-repetitions-max=9}
    ClientSd_CSI_SomeIp_COMP_SOMEIP_UDP_E2E_Pr6_Service: initial-find-behavior={initial-delay-max-value=0.035, initial-delay-min-value=0.035, initial-repetitions-base-delay=0.04, initial-repetitions-max=9}
    ClientSd_CSI_SomeIp_COMP_SOMEIP_UDP_E2E_Pr7_Service: initial-find-behavior={initial-delay-max-value=0.035, initial-delay-min-value=0.035, initial-repetitions-base-delay=0.04, initial-repetitions-max=9}
    ClientSd_CSI_SomeIp_COMP_SOMEIP_UDP_Service: initial-find-behavior={initial-delay-max-value=0.035, initial-delay-min-value=0.035, initial-repetitions-base-delay=0.04, initial-repetitions-max=9}
    ClientSd_CSI_SomeIp_ECU7_basicIPC_Service: initial-find-behavior={initial-delay-max-value=0.035, initial-delay-min-value=0.035, initial-repetitions-base-delay=0.04, initial-repetitions-max=9}
  4 x someip sd server event group timing config, all with request-response-delay={max-value=0, min-value=0}:
    ServerEgSd_SomeIpECU7_SOMEIP_UDP_E2E_Pr7_Event
    ServerEgSd_SomeIpECU7_SOMEIP_UDP_E2E_Pr7_Event1
    ServerEgSd_SomeIpECU7_SOMEIP_UDP_Event
    ServerEgSd_SomeIpECU_STAT
  4 x someip sd server service instance config, all with offer-cyclic-delay=10, request-response-delay={max-value=0, min-value=0}, service-offer-time-to-live=16777215:
    ServerSd_PSI_ECU_Stat_ECU7_Service_ST3: initial-offer-behavior={initial-delay-max-value=0.15, initial-delay-min-value=0.15, initial-repetitions-base-delay=0.15, initial-repetitions-max=2}
    ServerSd_PSI_SomeIp_ECU7_SOMEIP_UDP_E2E_Pr6_Service: initial-offer-behavior={initial-delay-max-value=0.035, initial-delay-min-value=0.035, initial-repetitions-base-delay=0.15, initial-repetitions-max=2}
    ServerSd_PSI_SomeIp_ECU7_SOMEIP_UDP_E2E_Pr7_Service: initial-offer-behavior={initial-delay-max-value=0.035, initial-delay-min-value=0.035, initial-repetitions-base-delay=0.15, initial-repetitions-max=2}
    ServerSd_PSI_SomeIp_ECU7_SOMEIP_UDP_Service: initial-offer-behavior={initial-delay-max-value=0.035, initial-delay-min-value=0.035, initial-repetitions-base-delay=0.15, initial-repetitions-max=2}
package /ServiceInterfaces
  12 x service interface:
    COMP_SOMEIP_UDP_E2E_Pr6_Service
      namespaces:
        symbol props Ecu7Services
        symbol props NS_COMP_SOMEIP_UDP_E2E_Pr6_Service
      events:
        data COMP_SOMEIP_UDP_E2E_Pr6_Event: type=REC_TestSerialized_AdAR
    COMP_SOMEIP_UDP_E2E_Pr7_Service
      namespaces:
        symbol props Ecu7Services
        symbol props NS_COMP_SOMEIP_UDP_E2E_Pr7_Service
      events:
        data COMP_SOMEIP_UDP_E2E_Pr7_Event: type=REC_TestSerialized_AdAR
    COMP_SOMEIP_UDP_Service
      namespaces:
        symbol props Ecu7Services
        symbol props NS_COMP_SOMEIP_UDP_Service
      events:
        data COMP_SOMEIP_UDP_Event: type=REC_TestSerialized_AdAR
      methods:
        operation COMP_SOMEIP_UDP_Method: fire-and-forget=false
          arg ActualClientID: type=uint16_t, direction=IN
          arg TestSig: type=uint8_t, direction=IN
          arg ErrorStatus: type=uint8_t, direction=IN
    DI_OdoSpeedometer_Service_ST3
      namespaces:
        symbol props Ecu7Services
        symbol props NS_DI_OdoSpeedometer_Service_ST3
      events:
        data DI_OdoSpeedometer_ST3: type=REC_DI_Odo_Pr5_ST3
    ECU7_SOMEIP_UDP_E2E_Pr6_Service
      namespaces:
        symbol props Ecu7Services
        symbol props NS_ECU7_SOMEIP_UDP_E2E_Pr6_Service
      events:
        data ECU7_SOMEIP_UDP_E2E_Pr6_Event: type=REC_TestSerialized_AdAR
    ECU7_SOMEIP_UDP_E2E_Pr7_Service
      namespaces:
        symbol props Ecu7Services
        symbol props NS_ECU7_SOMEIP_UDP_E2E_Pr7_Service
      events:
        data ECU7_SOMEIP_UDP_E2E_Pr7_Event: type=REC_TestSerialized_AdAR
    ECU7_SOMEIP_UDP_Service
      namespaces:
        symbol props Ecu7Services
        symbol props NS_ECU7_SOMEIP_UDP_Service
      events:
        data ECU7_SOMEIP_UDP_Event: type=REC_TestSerialized_AdAR
      methods:
        operation ECU7_SOMEIP_UDP_Method: fire-and-forget=false
          arg ActualClientID: type=uint16_t, direction=IN
          arg TestSig: type=uint8_t, direction=IN
          arg ErrorStatus: type=uint8_t, direction=IN
    ECU7_basicIPC_Service
      namespaces:
        symbol props Ecu7Services
        symbol props NS_ECU7_basicIPC_Service
      events:
        data ECU7_basicIPC_Event: type=ARR_Uint32_348
    ECU_Stat_ECU7_Service_ST3
      namespaces:
        symbol props Ecu7Services
        symbol props NS_ECU_Stat_ECU7_Service_ST3
      events:
        data ECU_Stat_ECU7_ST3: type=REC_ECU_Stat_ECU7_ST3
    Immobilizer_Master_Service_ST3
      namespaces:
        symbol props Ecu7Services
        symbol props NS_Immobilizer_Master_Service_ST3
      events:
        data Ign_Stat_ST3: type=REC_Ign_Stat_Pr5_ST3
    PN14_Master_Service_ST3
      namespaces:
        symbol props Ecu7Services
        symbol props NS_PN14_Master_Service_ST3
      events:
        data PN14_Master_Stat1_ST3: type=REC_PN14_Master_Stat1_ST3
    PT4_PTCoor_Service_ST3
      namespaces:
        symbol props Ecu7Services
        symbol props NS_PT4_PTCoor_Service_ST3
      events:
        data PT4_PTCoor4_ST3: type=REC_PT4_PTCoor4_Pr5_ST3
package /ServiceInterfaces/InterfaceMappingSets
  interface mapping set InterfaceMappingSet
    5 x interface mapping:
      DI_OdoSpeedometer_Service_ST3_InterfaceMapping
        event mapping DI_OdoSpeedometer_ST3_DI_Odo_Pr5_ST3: data-element=DI_Odo_Pr5_ST3, event=DI_OdoSpeedometer_ST3
      ECU_Stat_ECU7_Service_ST3_InterfaceMapping
        6 x event mapping, all with event=ECU_Stat_ECU7_ST3:
          Awake_Diag_Actv_ECU7_ST3_Awake_Diag_Actv_ECU7_ST3: data-element=Awake_Diag_Actv_ECU7_ST3
          Awake_HAD_Actv_ECU7_ST3_Awake_HAD_Actv_ECU7_ST3: data-element=Awake_HAD_Actv_ECU7_ST3
          Awake_Ignition_On_ECU7_ST3_Awake_Ignition_On_ECU7_ST3: data-element=Awake_Ignition_On_ECU7_ST3
          Awake_NwStart_ECU7_ST3_Awake_NwStart_ECU7_ST3: data-element=Awake_NwStart_ECU7_ST3
          ECU_Id_ECU7_ST3_ECU_Id_ECU7_ST3: data-element=ECU_Id_ECU7_ST3
          WakeupRsn_ECU7_ST3_WakeupRsn_ECU7_ST3: data-element=WakeupRsn_ECU7_ST3
      Immobilizer_Master_Service_ST3_InterfaceMapping
        event mapping Ign_Stat_ST3_Ign_Stat_Pr5_ST3: data-element=Ign_Stat_Pr5_ST3, event=Ign_Stat_ST3
      PN14_Master_Service_ST3_InterfaceMapping
        event mapping PN14_ProdMd_Stat_ST3_PN14_ProdMd_Stat_ST3: data-element=PN14_ProdMd_Stat_ST3, event=PN14_Master_Stat1_ST3
        event mapping PN14_SupBat_Volt_ST3_PN14_SupBat_Volt_ST3: data-element=PN14_SupBat_Volt_ST3, event=PN14_Master_Stat1_ST3
        event mapping PN14_TransMd_Stat_ST3_PN14_TransMd_Stat_ST3: data-element=PN14_TransMd_Stat_ST3, event=PN14_Master_Stat1_ST3
      PT4_PTCoor_Service_ST3_InterfaceMapping
        event mapping PT4_PTCoor4_ST3_PT4_PTCoor4_Pr5_ST3: data-element=PT4_PTCoor4_Pr5_ST3, event=PT4_PTCoor4_ST3
package /ServiceInterfaces/ServiceInterfaceDeployments
  5 x signal based service interface deployment:
    CSI_DI_OdoSpeedometer_Service_ST3_SignalBasedDeployment: service-interface=DI_OdoSpeedometer_Service_ST3
    CSI_Immobilizer_Master_Service_ST3_SignalBasedDeployment: service-interface=Immobilizer_Master_Service_ST3
    CSI_PN14_Master_Service_ST3_SignalBasedDeployment: service-interface=PN14_Master_Service_ST3
    CSI_PT4_PTCoor_Service_ST3_SignalBasedDeployment: service-interface=PT4_PTCoor_Service_ST3
    PSI_ECU_Stat_ECU7_Service_ST3_SignalBasedDeployment: service-interface=ECU_Stat_ECU7_Service_ST3
  12 x someip service interface deployment, all with service-interface-version={major-version=1, minor-version=0}:
    SomeIpCOMP_SOMEIP_UDP_E2E_Pr6_Service: service-interface=COMP_SOMEIP_UDP_E2E_Pr6_Service, service-interface-id=15238
      someip event deployment SomeIpCOMP_SOMEIP_UDP_E2E_Pr6_Event: event=COMP_SOMEIP_UDP_E2E_Pr6_Event, event-id=1, transport-protocol=UDP
      someip event group COMP_SOMEIP_UDP_E2E_Pr6_Event: event-group-id=1, event=SomeIpCOMP_SOMEIP_UDP_E2E_Pr6_Event
    SomeIpCOMP_SOMEIP_UDP_E2E_Pr7_Service: service-interface=COMP_SOMEIP_UDP_E2E_Pr7_Service, service-interface-id=15236
      someip event deployment SomeIpCOMP_SOMEIP_UDP_E2E_Pr7_Event: event=COMP_SOMEIP_UDP_E2E_Pr7_Event, event-id=1, transport-protocol=UDP
      someip event group COMP_SOMEIP_UDP_E2E_Pr7_Event: event-group-id=1, event=SomeIpCOMP_SOMEIP_UDP_E2E_Pr7_Event
    SomeIpCOMP_SOMEIP_UDP_Service: service-interface=COMP_SOMEIP_UDP_Service, service-interface-id=15234
      someip event deployment SomeIpCOMP_SOMEIP_UDP_Event: event=COMP_SOMEIP_UDP_Event, event-id=1, transport-protocol=UDP
      someip method deployment SomeIpCOMP_SOMEIP_UDP_Method: method=COMP_SOMEIP_UDP_Method, method-id=1, transport-protocol=UDP
      someip event group COMP_SOMEIP_UDP_Event: event-group-id=1, event=SomeIpCOMP_SOMEIP_UDP_Event
    SomeIpDI_OdoSpeedometer_Service_ST3: service-interface=DI_OdoSpeedometer_Service_ST3, service-interface-id=12804
      someip event deployment SomeIpDI_OdoSpeedometer_ST3: event=DI_OdoSpeedometer_ST3, event-id=0, transport-protocol=UDP
      someip event group DI_Master_Odometer: event-group-id=0, event=SomeIpDI_OdoSpeedometer_ST3
    SomeIpECU7_SOMEIP_UDP_E2E_Pr6_Service: service-interface=ECU7_SOMEIP_UDP_E2E_Pr6_Service, service-interface-id=15237
      someip event deployment SomeIpECU7_SOMEIP_UDP_E2E_Pr6_Event: event=ECU7_SOMEIP_UDP_E2E_Pr6_Event, event-id=1, transport-protocol=UDP
      someip event group ECU7_SOMEIP_UDP_E2E_Pr7_Event: event-group-id=1, event=SomeIpECU7_SOMEIP_UDP_E2E_Pr6_Event
    SomeIpECU7_SOMEIP_UDP_E2E_Pr7_Service: service-interface=ECU7_SOMEIP_UDP_E2E_Pr7_Service, service-interface-id=15235
      someip event deployment SomeIpECU7_SOMEIP_UDP_E2E_Pr7_Event: event=ECU7_SOMEIP_UDP_E2E_Pr7_Event, event-id=1, transport-protocol=UDP
      someip event group ECU7_SOMEIP_UDP_E2E_Pr7_Event: event-group-id=1, event=SomeIpECU7_SOMEIP_UDP_E2E_Pr7_Event
    SomeIpECU7_SOMEIP_UDP_Service: service-interface=ECU7_SOMEIP_UDP_Service, service-interface-id=15233
      someip event deployment SomeIpECU7_SOMEIP_UDP_Event: event=ECU7_SOMEIP_UDP_Event, event-id=1, transport-protocol=UDP
      someip method deployment SomeIpECU7_SOMEIP_UDP_Method: method=ECU7_SOMEIP_UDP_Method, method-id=1, transport-protocol=UDP
      someip event group ECU7_SOMEIP_UDP_Event: event-group-id=1, event=SomeIpECU7_SOMEIP_UDP_Event
    SomeIpECU7_basicIPC_Service: service-interface=ECU7_basicIPC_Service, service-interface-id=15239
      someip event deployment SomeIpECU7_basicIPC_Event: event=ECU7_basicIPC_Event, event-id=1, transport-protocol=UDP
      someip event group ECU7_basicIPC_Event: event-group-id=1, event=SomeIpECU7_basicIPC_Event
    SomeIpECU_Stat_ECU7_Service_ST3: service-interface=ECU_Stat_ECU7_Service_ST3, service-interface-id=15232
      someip event deployment SomeIpECU_Stat_ECU7_ST3: event=ECU_Stat_ECU7_ST3, event-id=1, transport-protocol=UDP
      someip event group ECU_STAT: event-group-id=1, event=SomeIpECU_Stat_ECU7_ST3
    SomeIpImmobilizer_Master_Service_ST3: service-interface=Immobilizer_Master_Service_ST3, service-interface-id=128
      someip event deployment SomeIpIgn_Stat_ST3: event=Ign_Stat_ST3, event-id=0, transport-protocol=UDP
      someip event group Ign_Stat: event-group-id=0, event=SomeIpIgn_Stat_ST3
    SomeIpPN14_Master_Service_ST3: service-interface=PN14_Master_Service_ST3, service-interface-id=14720
      someip event deployment SomeIpPN14_Master_Stat1_ST3: event=PN14_Master_Stat1_ST3, event-id=0, transport-protocol=UDP
      someip event group PN14_Master: event-group-id=0, event=SomeIpPN14_Master_Stat1_ST3
    SomeIpPT4_PTCoor_Service_ST3: service-interface=PT4_PTCoor_Service_ST3, service-interface-id=14596
      someip event deployment SomeIpPT4_PTCoor4_ST3: event=PT4_PTCoor4_ST3, event-id=6, transport-protocol=UDP
      someip event group PT4_PTCoor4: event-group-id=0, event=SomeIpPT4_PTCoor4_ST3
  user defined service interface deployment UD_ECU7_basicIPC_Service: service-interface=ECU7_basicIPC_Service
    user defined event deployment ECU7_basicIPC_Event: event=ECU7_basicIPC_Event
  user defined service interface deployment DiagComApi_Binding: service-interface=DiagComApi
    user defined event deployment DaemonRequestResponse: event=DaemonRequestResponse
    user defined event deployment DiagRequest: event=DiagRequest
    4 x user defined method deployment:
      RequestData: method=RequestData
      Cancel: method=Cancel
      NotifyValue: method=NotifyValue
      NotifyResponse: method=NotifyResponse
package /ServiceInterfaces/TransformationPropsSet
  transformation props set Transformer_Configuration_Package
    ap someip transformation props SOME_IP_8Bit: alignment=8, byte-order=little-endian, is-dynamic-length-field-size=false, string-encoding=UTF-8
    ap someip transformation props SOME_IP_8Bit1: alignment=8, byte-order=little-endian, is-dynamic-length-field-size=false, string-encoding=UTF-8
    ap someip transformation props SOME_IP_8Bit_Profile_6: alignment=8, byte-order=little-endian, is-dynamic-length-field-size=false, string-encoding=UTF-8
package /ServiceInterfaces/TransformationPropsToServiceInterfaceMappingSets
  transformation props to service interface element mapping set TransformationPropsToServiceInterfaceElementMappingSet
    14 x transformation props to service interface element mapping:
      COMP_SOMEIP_UDP_E2E_Pr6_EventTransProps: event=COMP_SOMEIP_UDP_E2E_Pr6_Event, transformation-props=SOME_IP_8Bit_Profile_6
      COMP_SOMEIP_UDP_E2E_Pr7_EventTransProps: event=COMP_SOMEIP_UDP_E2E_Pr7_Event, transformation-props=SOME_IP_8Bit1
      COMP_SOMEIP_UDP_EventTransProps: event=COMP_SOMEIP_UDP_Event, transformation-props=SOME_IP_8Bit1
      COMP_SOMEIP_UDP_MethodTransProps: method=COMP_SOMEIP_UDP_Method, transformation-props=SOME_IP_8Bit
      DI_OdoSpeedometer_ST3TransProps: event=DI_OdoSpeedometer_ST3, transformation-props=SOME_IP_8Bit1
      ECU7_SOMEIP_UDP_E2E_Pr6_EventTransProps: event=ECU7_SOMEIP_UDP_E2E_Pr6_Event, transformation-props=SOME_IP_8Bit_Profile_6
      ECU7_SOMEIP_UDP_E2E_Pr7_EventTransProps: event=ECU7_SOMEIP_UDP_E2E_Pr7_Event, transformation-props=SOME_IP_8Bit1
      ECU7_SOMEIP_UDP_EventTransProps: event=ECU7_SOMEIP_UDP_Event, transformation-props=SOME_IP_8Bit1
      ECU7_SOMEIP_UDP_MethodTransProps: method=ECU7_SOMEIP_UDP_Method, transformation-props=SOME_IP_8Bit
      ECU7_basicIPC_EventTransProps: event=ECU7_basicIPC_Event, transformation-props=SOME_IP_8Bit1
      ECU_Stat_ECU7_ST3TransProps: event=ECU_Stat_ECU7_ST3, transformation-props=SOME_IP_8Bit1
      Ign_Stat_ST3TransProps: event=Ign_Stat_ST3, transformation-props=SOME_IP_8Bit1
      PN14_Master_Stat1_ST3TransProps: event=PN14_Master_Stat1_ST3, transformation-props=SOME_IP_8Bit1
      PT4_PTCoor4_ST3TransProps: event=PT4_PTCoor4_ST3, transformation-props=SOME_IP_8Bit1
package /SoftwareTypes/Interfaces
  12 x sender receiver interface, all with category=FUNCTIONAL:
    IF_Awake_Diag_Actv_ECU7_ST3  # Stay awake for diagnostics active
      data Awake_Diag_Actv_ECU7_ST3: sw-calibration-access=READ-WRITE  # SHORT: Stay awake for diagnostics active
    IF_Awake_HAD_Actv_ECU7_ST3  # Stay awake for HAD active
      data Awake_HAD_Actv_ECU7_ST3: sw-calibration-access=READ-WRITE  # SHORT: Stay awake for HAD active
    IF_Awake_Ignition_On_ECU7_ST3  # Stay awake for ignition on from ECU7
      data Awake_Ignition_On_ECU7_ST3: sw-calibration-access=READ-WRITE  # SHORT: Stay awake for ignition on from ECU7
    IF_Awake_NwStart_ECU7_ST3  # Stay awake for network startup
      data Awake_NwStart_ECU7_ST3: sw-calibration-access=READ-WRITE  # SHORT: Stay awake for network startup
    IF_ECU_Id_ECU7_ST3  # ECU identifier
      data ECU_Id_ECU7_ST3: sw-calibration-access=READ-WRITE  # SHORT: ECU identifier LONG: XX -> <ECU Type> Default Value ist immer die entsprechende ECU-ID (wird in einer separaten Liste gepflegt)
    IF_PN14_ProdMd_Stat_ST3: invalidation-policy{data-element=PN14_ProdMd_Stat_ST3, handle-invalid=DONT-INVALIDATE}  # Powernet production mode state
      data PN14_ProdMd_Stat_ST3: sw-calibration-access=READ-WRITE  # SHORT: Powernet production mode state LONG: Powernet production mode state
    IF_PN14_SupBat_Volt_ST3: invalidation-policy{data-element=PN14_SupBat_Volt_ST3, handle-invalid=DONT-INVALIDATE}  # Supply battery voltage
      data PN14_SupBat_Volt_ST3: sw-calibration-access=READ-WRITE  # SHORT: Supply battery voltage LONG: Supply battery voltage
    IF_PN14_TransMd_Stat_ST3: invalidation-policy{data-element=PN14_TransMd_Stat_ST3, handle-invalid=DONT-INVALIDATE}  # Powernet transport mode status
      data PN14_TransMd_Stat_ST3: sw-calibration-access=READ-WRITE  # SHORT: Powernet transport mode status LONG: Powernet transport mode status
    IF_WakeupRsn_ECU7_ST3  # Wakeup reason
      data WakeupRsn_ECU7_ST3: sw-calibration-access=READ-WRITE  # SHORT: Wakeup reason LONG: XX -> <ECU type> Table with global wakeup reasons, i.e. every ECU uses the same data type
    IG_DI_Odo_Pr5_ST3: invalidation-policy{data-element=DI_Odo_Pr5_ST3, handle-invalid=DONT-INVALIDATE}  # DriverInformation Odometer
      data DI_Odo_Pr5_ST3: sw-calibration-access=READ-WRITE  # SHORT: DriverInformation Odometer LONG: DriverInformation Odometer
    IG_Ign_Stat_Pr5_ST3: invalidation-policy{data-element=Ign_Stat_Pr5_ST3, handle-invalid=DONT-INVALIDATE}  # Ignition state
      data Ign_Stat_Pr5_ST3: sw-calibration-access=READ-WRITE  # SHORT: Ignition state LONG: Ignition state
    IG_PT4_PTCoor4_Pr5_ST3: invalidation-policy{data-element=PT4_PTCoor4_Pr5_ST3, handle-invalid=DONT-INVALIDATE}  # PT4_PTCoor4_Pr5_ST3
      data PT4_PTCoor4_Pr5_ST3: sw-calibration-access=READ-WRITE  # SHORT: PT4_PTCoor4_Pr5_ST3 LONG: PT4_PTCoor4_Pr5_ST3
package /Topology/Clusters
  ethernet cluster Eth_Cluster4: baudrate=100000000, protocol-name=ETHERNET
    ethernet physical channel ChannelCommunication20: category=WIRED
      pdu triggering DI_OdoSpeedometer_ST3_7jb3acjj567zcinfjaciyzmox: pdu=DI_OdoSpeedometer_ST3, to ECU7_ExecutionContext1
      pdu triggering Ign_Stat_ST3_30i7ve981yksfyg7upd5w1x1e: pdu=Ign_Stat_ST3, to ECU7_ExecutionContext1
      pdu triggering PN14_Master_Stat1_ST3_1c1yt5wkb7eltvmd1nhzl575e: pdu=PN14_Master_Stat1_ST3, to ECU7_ExecutionContext1
      pdu triggering PT4_PTCoor4_ST3_1rx6hv5wn01u44037z5f7jia2: pdu=PT4_PTCoor4_ST3, to ECU7_ExecutionContext1
      pdu triggering pduTrCOMP_SOMEIP_UDP_E2E_Pr6_Event_P_COMP_SOMEIP_UDP_E2E_Pr6_Service_R_COMP_SOMEIP_UDP_E2E_Pr6_Service: pdu=pduCOMP_SOMEIP_UDP_E2E_Pr6_Event_P_COMP_SOMEIP_UDP_E2E_Pr6_Service_R_COMP_SOMEIP_UDP_E2E_Pr6_Service, to ECU7_ExecutionContext1
      pdu triggering pduTrCOMP_SOMEIP_UDP_E2E_Pr7_Event_P_COMP_SOMEIP_UDP_E2E_Pr7_Service_R_COMP_SOMEIP_UDP_E2E_Pr7_Service: pdu=pduCOMP_SOMEIP_UDP_E2E_Pr7_Event_P_COMP_SOMEIP_UDP_E2E_Pr7_Service_R_COMP_SOMEIP_UDP_E2E_Pr7_Service, to ECU7_ExecutionContext1
      pdu triggering pduTrCOMP_SOMEIP_UDP_Event_P_COMP_SOMEIP_UDP_Service_R_COMP_SOMEIP_UDP_Service: pdu=pduCOMP_SOMEIP_UDP_Event_P_COMP_SOMEIP_UDP_Service_R_COMP_SOMEIP_UDP_Service, to ECU7_ExecutionContext1
      pdu triggering pduTrCOMP_SOMEIP_UDP_Method_NONE_P_COMP_SOMEIP_UDP_Service_R_COMP_SOMEIP_UDP_Service_return: pdu=pduCOMP_SOMEIP_UDP_Method_NONE_P_COMP_SOMEIP_UDP_Service_R_COMP_SOMEIP_UDP_Service_return, to ECU7_ExecutionContext1
      pdu triggering pduTrCOMP_SOMEIP_UDP_Method_NONE_R_COMP_SOMEIP_UDP_Service_P_COMP_SOMEIP_UDP_Service_call: pdu=pduCOMP_SOMEIP_UDP_Method_NONE_R_COMP_SOMEIP_UDP_Service_P_COMP_SOMEIP_UDP_Service_call, from ECU7_ExecutionContext1
      pdu triggering pduTrECU7_SOMEIP_UDP_E2E_Pr6_Event_P_ECU7_SOMEIP_UDP_E2E_Pr6_Service_R_ECU7_SOMEIP_UDP_E2E_Pr6_Service: pdu=pduECU7_SOMEIP_UDP_E2E_Pr6_Event_P_ECU7_SOMEIP_UDP_E2E_Pr6_Service_R_ECU7_SOMEIP_UDP_E2E_Pr6_Service, from ECU7_ExecutionContext1
      pdu triggering pduTrECU7_SOMEIP_UDP_E2E_Pr7_Event_P_ECU7_SOMEIP_UDP_E2E_Pr7_Service_R_ECU7_SOMEIP_UDP_E2E_Pr7_Service: pdu=pduECU7_SOMEIP_UDP_E2E_Pr7_Event_P_ECU7_SOMEIP_UDP_E2E_Pr7_Service_R_ECU7_SOMEIP_UDP_E2E_Pr7_Service, from ECU7_ExecutionContext1
      pdu triggering pduTrECU7_SOMEIP_UDP_Event_P_ECU7_SOMEIP_UDP_Service_R_ECU7_SOMEIP_UDP_Service: pdu=pduECU7_SOMEIP_UDP_Event_P_ECU7_SOMEIP_UDP_Service_R_ECU7_SOMEIP_UDP_Service, from ECU7_ExecutionContext1
      pdu triggering pduTrECU7_SOMEIP_UDP_Method_NONE_P_ECU7_SOMEIP_UDP_Service_R_ECU7_SOMEIP_UDP_Service_return: pdu=pduECU7_SOMEIP_UDP_Method_NONE_P_ECU7_SOMEIP_UDP_Service_R_ECU7_SOMEIP_UDP_Service_return, from ECU7_ExecutionContext1
      pdu triggering pduTrECU7_SOMEIP_UDP_Method_NONE_R_ECU7_SOMEIP_UDP_Service_P_ECU7_SOMEIP_UDP_Service_call: pdu=pduECU7_SOMEIP_UDP_Method_NONE_R_ECU7_SOMEIP_UDP_Service_P_ECU7_SOMEIP_UDP_Service_call, to ECU7_ExecutionContext1
      pdu triggering pduTrECU7_basicIPC_Event_P_ECU7_basicIPC_Service_R_ECU7_basicIPC_Service: pdu=pduECU7_basicIPC_Event_P_ECU7_basicIPC_Service_R_ECU7_basicIPC_Service, to ECU7_ExecutionContext1
      network endpoint NE_EthernetECUInterface_ECU7_CTP_Cluster_0: network-endpoint-addresses=ipv-4-configuration={ipv-4-address=10.20.1.7, network-mask=255.255.0.0}
      network endpoint NE_SomeIP_SD_NetworkEndpoint_Eth_Cluster_4_20: network-endpoint-addresses=ipv-4-configuration={ipv-4-address=239.20.0.2, ipv-4-address-source=FIXED, network-mask=255.255.0.0}
      vlan Eth_Cluster4_20: vlan-identifier=20
    ethernet physical channel Eth_Cluster4_127: category=WIRED
      pdu triggering ECU7_Cluster4_SD_Ctrl_Rx_Multicast_TRIGGERING: pdu=SD_Ctrl_Rx_Multicast, to ECU7_ExecutionContext1
      pdu triggering ECU7_Cluster4_SD_Ctrl_Rx_TRIGGERING: pdu=SD_Ctrl_Rx, to ECU7_ExecutionContext1
      pdu triggering ECU7_Cluster4_SD_Ctrl_Tx_TRIGGERING: pdu=SD_Ctrl_Tx, from ECU7_ExecutionContext1
      pdu triggering ECU_Stat_ECU7_ST3_8vj2ivjbu2c0awr5fsb06go3x: pdu=ECU_Stat_ECU7_ST3, from ECU7_ExecutionContext1
      network endpoint NE_SomeIP_SD_NetworkEndpoint_Eth_Cluster_4_127: network-endpoint-addresses=ipv-4-configuration={ipv-4-address=239.127.0.2, ipv-4-address-source=FIXED, network-mask=255.255.0.0}
      network endpoint NE_fixed_10_127_1_7: network-endpoint-addresses=ipv-4-configuration={ipv-4-address=10.127.1.7, ipv-4-address-source=FIXED, network-mask=255.255.0.0, ttl=1}, priority=5
      vlan Eth_Cluster4_127: vlan-identifier=127
package /Topology/HardwareComponents
  machine design ECU7_ExecutionContext1: category=EXECUTION_CONTEXT
    ethernet communication connector ECU7_ExecutionContext1_BusSystem20: category=WIRED, maximum-transmission-unit=1500, neighbor-cache-size=128, unicast-network-endpoint=NE_fixed_10_127_1_7
    ethernet communication connector EthernetECUInterface_ECU7_ExecutionContext1: category=WIRED, unicast-network-endpoint=NE_EthernetECUInterface_ECU7_CTP_Cluster_0
    service-discover-configs:
      multicast-sd-ip-address=NE_SomeIP_SD_NetworkEndpoint_Eth_Cluster_4_20, someip-service-discovery-port=30490
      multicast-sd-ip-address=NE_SomeIP_SD_NetworkEndpoint_Eth_Cluster_4_127, someip-service-discovery-port=30490
package /amsr/diag
  service interface DiagComApi
    namespaces:
      4 x symbol props:
        amsr
        diag
        service_interfaces
        diag_com_api
    events:
      data DaemonRequestResponse: type=DaemonRequestResponseType
      data DiagRequest: type=DiagRequestType
    methods:
      4 x operation, all with fire-and-forget=true:
        RequestData
          6 x arg, all with direction=IN:
            handle: type=HandleType
            instance_handle: type=InstanceHandle
            job_identifier: type=JobIdentifier
            meta_info: type=MetaInfoType
            request_data: type=types/ByteVectorType
            conversation_handle: type=ConversationHandle
        Cancel
          arg job_identifier: type=JobIdentifier, direction=IN
        NotifyValue
          4 x arg, all with direction=IN:
            handle: type=HandleType
            instance_handle: type=InstanceHandle
            conversation_handle: type=ConversationHandle
            byte_vector: type=types/ByteVectorType
        NotifyResponse
          arg response_type: type=HandleType, direction=IN
          arg job_identifier: type=JobIdentifier, direction=IN
          arg byte_vector: type=types/ByteVectorType, direction=IN
package /ara/diag
  adaptive application sw component type DiagnosticManagerSwc
    provide/require port Persistency: provided-required-interface=PersistencyInterface
    require port DiagComApiDeamonPort: required-interface=DiagComApi
package /SoftwareDistribution/SoftwareCluster
  software cluster SoftwareClusterPlatform: contained-process=[Application_basicIPC1_Process, Application_basicIPC2_Process, DiagnosticManagerDeamon, SelfDiagnosticAgent_Process, Application_S2S_Process, Application_SOMEIP_Process], design=temporarySoftwareClusterDesignPer, diagnostic-extract=DcmContributionSet, vendor-id=4660, version=1.0.0.0000
    diagnostic-addresss:
      address-semantics=PHYSICAL-ADDRESS, diagnostic-address=1
      address-semantics=FUNCTIONAL-ADDRESS, diagnostic-address=2
      address-semantics=FUNCTIONAL-ADDRESS, diagnostic-address=3
package /SoftwareDistribution/SoftwarePackage
  software package SoftwarePackagePlatform: software-cluster=SoftwareClusterPlatform
package /SoftwareDistribution/SoftwareClusterDesign
  software cluster design temporarySoftwareClusterDesignPer: contained-process=[Application_basicIPC1_ProcessDesign, Application_basicIPC2_ProcessDesign, DiagnosticManagerDeamonDesign, Application_S2S_ProcessDesign, SelfDiagnosticAgent_ProcessDesign, Application_SOMEIP_ProcessDesign], intended-target-machine=ECU7_ExecutionContext1
package /Diagnostics/port_interfaces
  diagnostic condition interface Condition_Interface
  diagnostic dtc information interface DTC_Information_Interface
  diagnostic data identifier generic interface DataIdentifierGeneric_Interface
  6 x diagnostic data identifier interface:
    VersionInfoDataIdentifier
      namespaces:
        symbol props lorem
        symbol props ipsum
      read Read
        arg VersionInfoBuffer: type=ByteVector, direction=OUT
    VINInformation_Interface
      read Read
        arg Vin: type=VINType, direction=OUT
      write Write
        arg Vin: type=VINType, direction=IN
    SystemInfoDataIdentifier
      namespaces:
        symbol props lorem
        symbol props ipsum
      read Read
        arg SystemInfoBuffer: type=ByteVector, direction=OUT
    SwucDataIdentifiers
      namespaces:
        symbol props lorem
        symbol props ipsum
      read Read
        arg Buffer: type=ByteVector, direction=OUT
    Vehicle_Odometer_in_Low_Resolution
      namespaces:
        symbol props lorem
        symbol props ipsum
      read Read
        arg vehicle_odometer_res: type=uint16_t, direction=OUT
    ActiveDiagnosticInformation_Interface
      namespaces:
        symbol props lorem
        symbol props ipsum
      read Read
        arg Identification: type=IdentificationArray, direction=OUT
        arg Session: type=uint8_t, direction=OUT
  diagnostic do ip group identification interface DoIPGroupIdentification_Interface
  diagnostic do ip power mode interface DoIPPowerMode_Interface
  diagnostic download interface Download_Interface
  diagnostic event interface Event_Interface
  diagnostic generic uds interface Generic_Uds_Interface
  diagnostic indicator interface Indicator_Interface
  diagnostic monitor interface Monitor_Interface
  diagnostic operation cycle interface OperationCycle_Interface
  diagnostic routine generic interface RoutineGeneric_Interface
  diagnostic routine interface Prepare_Vehicle_Systems_For_Reprogramming_Interface
    namespaces:
      symbol props lorem
      symbol props ipsum
    request result RequestResults
      arg response: type=uint8_t, direction=OUT
    start Start
      arg array: type=ArrayBytes2, direction=IN
      arg out_param: type=uint8_t, direction=OUT
    stop Stop
      arg response: type=uint8_t, direction=OUT
  diagnostic security level interface SecurityLevel_Interface
  diagnostic service validation interface ServiceValidation_Interface
  diagnostic upload interface Upload_Interface
package /Diagnostics/types
  13 x std cpp implementation data type, all with type-emitter=TYPE_EMITTER_ARA:
    VINType: category=ARRAY, array-size=17, cpp-template-argument=uint8_t  # 17 byte array of uint8 representing the VIN
      namespaces:
        symbol props ara
        symbol props diag
    ArrayBytes7: category=ARRAY, array-size=7, cpp-template-argument=uint8_t  # byte array of 7 bytes
      namespaces:
        symbol props self_diag_agent
    ByteVector: category=VECTOR, cpp-template-argument=uint8_t  # Vector of uint8
      namespaces:
        symbol props self_diag_agent
    InstanceHandle: type-reference=uint32_t
      namespaces:
        symbol props ns0: symbol=amsr
        symbol props ns1: symbol=diag
        symbol props ns2: symbol=com_api
    DiagRequestType: category=STRUCTURE
      namespaces:
        symbol props ns0: symbol=amsr
        symbol props ns1: symbol=diag
        symbol props ns2: symbol=com_api
      5 x cpp implementation data type element:
        handle: type-reference=HandleType
        instance_handle: type-reference=InstanceHandle
        conversation_handle: type-reference=ConversationHandle
        job_identifier: type-reference=JobIdentifier
        value: type-reference=types/ByteVectorType
    ConversationHandle: type-reference=uint16_t
      namespaces:
        symbol props ns0: symbol=amsr
        symbol props ns1: symbol=diag
        symbol props ns2: symbol=com_api
    HandleType: type-reference=uint16_t
      namespaces:
        symbol props ns0: symbol=amsr
        symbol props ns1: symbol=diag
        symbol props ns2: symbol=com_api
    MetaInfoType: category=ASSOCIATIVE_MAP, template-arguments=[string, string]  # Meta-Inf map, which contains key-value pairs of MetaInfoKeyType, MetaInfoValueType.
      namespaces:
        symbol props ns0: symbol=amsr
        symbol props ns1: symbol=diag
        symbol props ns2: symbol=com_api
    ByteVectorType: category=VECTOR, cpp-template-argument=uint8_t
      namespaces:
        symbol props ns0: symbol=amsr
        symbol props ns1: symbol=diag
        symbol props ns2: symbol=com_api
    JobIdentifier: type-reference=uint32_t
      namespaces:
        symbol props ns0: symbol=amsr
        symbol props ns1: symbol=diag
        symbol props ns2: symbol=com_api
    DaemonRequestResponseType: category=STRUCTURE
      namespaces:
        symbol props ns0: symbol=amsr
        symbol props ns1: symbol=diag
        symbol props ns2: symbol=com_api
      cpp implementation data type element response_type: type-reference=HandleType
      cpp implementation data type element job_identifier: type-reference=JobIdentifier
      cpp implementation data type element value: type-reference=types/ByteVectorType
    ArrayBytes2: category=ARRAY, array-size=2, cpp-template-argument=uint8_t  # byte array of 2 bytes
      namespaces:
        symbol props self_diag_agent
    IdentificationArray: category=ARRAY, array-size=3, cpp-template-argument=uint8_t  # byte array of 3 bytes
      namespaces:
        symbol props self_diag_agent
package /Diagnostics/Persistency
  persistency file array Deamon_PersistencyFileArray: update-strategy=KEEP-EXISTING, uri=../../per/DiagnosticManagerDeamonExecutable/etc/nv_data
  persistency file proxy interface PersistencyInterface: category=binary
  persistency port prototype to file array mapping PersistencyPortPrototypeToFileArrayMapping: persistency-file-array=Deamon_PersistencyFileArray, port-prototype=Application_basicIPC1_ExecutableRootSwc.Persistency, process=DiagnosticManagerDeamon
package /SelfDiagnosticAgent/Persistency
  persistency file array PersistencyFileArray_FileStorage: update-strategy=KEEP-EXISTING, uri=./etc
  persistency file proxy interface PersistencyInterface_FileSotrage_PRPort: category=text, update-strategy=KEEP-EXISTING, encoding=utf-8
  persistency key value database KeyValueStorage: update-strategy=KEEP-EXISTING, uri=./etc/kvs
  persistency key value database interface PersistencyInterface_PRPort: redundancy=NONE, update-strategy=DELETE, data-type-for-serialization=uint16_t
  persistency port prototype to file array mapping PersistencyPortProtToFileArrayMapping: persistency-file-array=PersistencyFileArray_FileStorage, port-prototype=SelfDiagnosticAgent_ExecutableRootSwc.prPortPrototype_FileStorage, process=SelfDiagnosticAgent_Process
  persistency port prototype to key value database mapping PersistencyPortProtToKeyValueDataBaseMapping: key-value-storage=KeyValueStorage, port-prototype=prPortPrototype_KeyValueStorage, process=SelfDiagnosticAgent_Process
package /SWUC_SDA_Interface/Deployment
  user defined service interface deployment SWUC_SDA_Interface_Deployment: service-interface=SWUC_SDA_ServiceInterface
    4 x user defined method deployment:
      GetSoftwarePartNumber: method=GetSoftwarePartNumbers
      GetSoftwareVersionInformation: method=GetSoftwareVersionInformation
      GetSoftwareVersionInformationShadow: method=GetSoftwareVersionInformationShadow
      GetHCPSoftwareInformation: method=GetHCPSoftwareInformation
package /SWUC_SDA_Interface/Design
  service interface SWUC_SDA_ServiceInterface
    namespaces:
      symbol props amsr
      symbol props swuc
    methods:
      4 x operation:
        GetSoftwarePartNumbers
          arg SoftwarePartNumbers: type=StringVector, direction=OUT
        GetSoftwareVersionInformation
          arg version_information_list: type=VersionInformationList, direction=OUT
        GetSoftwareVersionInformationShadow
          arg version_information_list: type=VersionInformationList, direction=OUT
        GetHCPSoftwareInformation
          arg hcp_software_information: type=HCPSoftwareInformation, direction=OUT
package /SWUC_SDA_Interface/Ipc/Required
  required user defined service instance RequiredIpcSWUC_SDA: service-interface=SWUC_SDA_Interface_Deployment
package /SWUC_SDA_Interface/Ipc/Required/Mapping
  service instance to port prototype mapping PortMappingProvidedIpcSWUC_SDA: port-prototype=SelfDiagnosticAgent_ExecutableRootSwc.SWUC_SDA, process=SelfDiagnosticAgent_Process, service-instance=RequiredIpcSWUC_SDA
package /SWUC/Types
  8 x std cpp implementation data type, all with type-emitter=TYPE_EMITTER_ARA:
    StringType: category=STRING
      namespaces:
        symbol props ns0: symbol=amsr
        symbol props ns1: symbol=swuc
    StringVector: category=VECTOR, cpp-template-argument=StringType
      namespaces:
        symbol props ns0: symbol=amsr
        symbol props ns1: symbol=swuc
    Uint16Vector: category=VECTOR, cpp-template-argument=uint16_t
      namespaces:
        symbol props ns0: symbol=amsr
        symbol props ns1: symbol=swuc
    ByteVectorType: category=VECTOR, cpp-template-argument=uint8_t
      namespaces:
        symbol props ns0: symbol=amsr
        symbol props ns1: symbol=diag
        symbol props ns2: symbol=com_api
    Uint8Vector: category=VECTOR, cpp-template-argument=uint8_t
      namespaces:
        symbol props ns0: symbol=amsr
        symbol props ns1: symbol=swuc
    VersionInformation: category=STRUCTURE
      namespaces:
        symbol props ns0: symbol=amsr
        symbol props ns1: symbol=swuc
      cpp implementation data type element year: type-reference=uint8_t
      cpp implementation data type element week: type-reference=uint8_t
      cpp implementation data type element patch_level: type-reference=uint8_t
    VersionInformationList: category=VECTOR, cpp-template-argument=VersionInformation
      namespaces:
        symbol props ns0: symbol=amsr
        symbol props ns1: symbol=swuc
    HCPSoftwareInformation: category=STRUCTURE
      namespaces:
        symbol props ns0: symbol=amsr
        symbol props ns1: symbol=swuc
      9 x cpp implementation data type element, all with type-reference=StringType:
        software_id
        software_name
        software_version
        software_type
        current_ram_consumption
        rom_consumption
        cpu_load
        running_state
        origin
